VERSION ""

NS_ :

BS_:

BU_: ICC DVR EPC BBCM EAMP CMSM SBOX FLZCU_HCU_IC FLZCU_IC HCU_IC FLZCU_Signal_IC CGW TBOX BNCM CWC FRZCU

BO_ 1265 ICC_ZCU_25: 24 ICC
 SG_ ICC_PwrOff : 18|1@0+ (1,0) [0|1] ""  FLZCU_HCU_IC
 SG_ ICC_EtmEgySave : 20|1@0+ (1,0) [0|1] ""  FLZCU_HCU_IC
 SG_ ICC_HoodSW : 23|2@0+ (1,0) [0|3] ""  FLZCU_HCU_IC
 SG_ ICC_GloveboxSW : 25|2@0+ (1,0) [0|3] ""  FLZCU_HCU_IC
 SG_ ICC_ChrgPortCover_Switch : 27|2@0+ (1,0) [0|3] ""  FLZCU_HCU_IC
 SG_ ICC_ReWinDefrstSwt : 29|2@0+ (1,0) [0|3] ""  FLZCU_HCU_IC,FLZCU_IC
 SG_ ICC_RearMirrorFoldCmd : 31|2@0+ (1,0) [0|3] ""  FLZCU_HCU_IC,FLZCU_IC
 SG_ ICC_CenterLockSwt : 33|2@0+ (1,0) [0|3] ""  FLZCU_HCU_IC,FLZCU_IC
 SG_ ICC_ReverseExtMirrorSts : 36|3@0+ (1,0) [0|7] ""  FLZCU_HCU_IC,FLZCU_IC
 SG_ ICC_LightMainSwitchSts : 39|3@0+ (1,0) [0|7] ""  FLZCU_HCU_IC
 SG_ ICC_AutoFoldSts : 41|2@0+ (1,0) [0|3] ""  FLZCU_HCU_IC,FLZCU_IC
 SG_ ICC_HeadlampHeightSts : 44|3@0+ (1,0) [0|7] ""  FLZCU_HCU_IC,FLZCU_IC
 SG_ ICC_WiprSnvty : 47|3@0+ (1,0) [0|7] ""  FLZCU_HCU_IC,FLZCU_IC
 SG_ ICC_WindowCmd : 52|5@0+ (1,0) [0|31] ""  FLZCU_HCU_IC,FLZCU_IC
 SG_ ICC_LowBeamDelayOff : 55|3@0+ (1,0) [0|7] ""  FLZCU_HCU_IC,FLZCU_IC
 SG_ ICC_FLWinCmd : 62|7@0+ (1,-1) [-1|100] "%"  FLZCU_HCU_IC,FLZCU_IC
 SG_ ICC_FRWinCmd : 86|7@0+ (1,-1) [-1|100] "%"  FLZCU_HCU_IC,FLZCU_IC
 SG_ ICC_RLWinCmd : 94|7@0+ (1,-1) [-1|100] "%"  FLZCU_HCU_IC,FLZCU_IC
 SG_ ICC_RRWinCmd : 102|7@0+ (1,-1) [-1|100] "%"  FLZCU_HCU_IC,FLZCU_IC
 SG_ ICC_FGHeatSts : 105|2@0+ (1,0) [0|3] ""  FLZCU_HCU_IC,FLZCU_IC
 SG_ ICC_AutolockSts : 107|2@0+ (1,0) [0|3] ""  FLZCU_HCU_IC,FLZCU_IC
 SG_ ICC_WiperID : 109|2@0+ (1,0) [0|3] ""  FLZCU_HCU_IC
 SG_ ICC_MaintenanceMode : 111|2@0+ (1,0) [0|3] ""  FLZCU_HCU_IC
 SG_ ICC_lockSetSwitchSts : 113|2@0+ (1,0) [0|3] ""  FLZCU_HCU_IC
 SG_ ICC_ChildLockSW : 115|2@0+ (1,0) [0|3] ""  FLZCU_HCU_IC
 SG_ ICC_ParkUnlockEnable : 117|2@0+ (1,0) [0|3] ""  FLZCU_HCU_IC,FLZCU_IC
 SG_ ICC_BLEOpenDriverDoorEnable : 119|2@0+ (1,0) [0|3] ""  FLZCU_HCU_IC,FLZCU_IC
 SG_ ICC_WinInhbSwt : 121|2@0+ (1,0) [0|3] ""  FLZCU_HCU_IC
 SG_ ICC_SteerWhlHeatgSwt : 124|3@0+ (1,0) [0|7] ""  FLZCU_HCU_IC,FLZCU_IC
 SG_ ICC_AutoHeatingset : 127|2@0+ (1,0) [0|3] ""  FLZCU_HCU_IC
 SG_ ICC_FrontFogSw : 145|2@0+ (1,0) [0|3] ""  FLZCU_HCU_IC
 SG_ ICC_RearFogSw : 147|2@0+ (1,0) [0|3] ""  FLZCU_HCU_IC
 SG_ ICC_DoorControlSW : 149|2@0+ (1,0) [0|3] ""  FLZCU_HCU_IC
 SG_ ICC_LockCarWinCloseSw : 151|2@0+ (1,0) [0|3] ""  FLZCU_HCU_IC,FLZCU_IC
 SG_ ICC_RainCarWinCloseSw : 159|2@0+ (1,0) [0|3] ""  FLZCU_HCU_IC
 SG_ ICC_EasyEntryExitSet : 157|2@0+ (1,0) [0|3] ""  FLZCU_HCU_IC,FLZCU_IC
 SG_ ICC_NapTimeSet : 166|6@0+ (1,-1) [-1|60] "min"  FLZCU_HCU_IC,FLZCU_IC
 SG_ ICC_NapAreaSet : 155|2@0+ (1,0) [0|3] ""  FLZCU_HCU_IC,FLZCU_IC
 SG_ ICC_NapStatusSet : 153|2@0+ (1,0) [0|3] ""  FLZCU_HCU_IC,FLZCU_IC
 SG_ ICC_NapCFSStatusSet : 175|2@0+ (1,0) [0|3] ""  FLZCU_HCU_IC,FRZCU
 SG_ ICC_NapSetTemperature : 173|5@0+ (0.5,15.5) [15.5|30.5] "℃"  FLZCU_HCU_IC,FRZCU
 SG_ ICC_SpoilerWelcomeFunSet : 183|2@0+ (1,0) [0|3] ""  FLZCU_HCU_IC
 SG_ ICC_SpoilerCtrlCmd : 181|3@0+ (1,0) [0|7] ""  FLZCU_HCU_IC
 SG_ ICC_HazardLightReq : 177|2@0+ (1,0) [0|3] ""  FLZCU_HCU_IC
 SG_ ICC_MusicStatus : 187|2@0+ (1,0) [0|3] ""  FLZCU_HCU_IC,FLZCU_IC
 SG_ ICC_CinemaStatus : 185|2@0+ (1,0) [0|3] ""  BBCM,FLZCU_HCU_IC,FLZCU_IC,HCU_IC

BO_ 1137 ICC_TBOX_27: 32 ICC
 SG_ ICC_ElectronicFenceStsFed_471h : 233|2@0+ (1,0) [0|3] ""  FLZCU_HCU_IC,HCU_IC
 SG_ ICC_GPSSailingSpeed_471h : 189|6@0+ (0.1,0) [0|6.3] ""  FLZCU_HCU_IC,HCU_IC
 SG_ ICC_BookChrgSetReq : 23|2@0+ (1,0) [0|3] ""  FLZCU_HCU_IC,HCU_IC,TBOX
 SG_ ICC_BkChrgStartTimeYear : 31|16@0+ (1,1900) [1900|9999] "年"  FLZCU_HCU_IC,HCU_IC,TBOX
 SG_ ICC_BkChrgStartTimeDay : 47|5@0+ (1,0) [1|31] "日"  FLZCU_HCU_IC,HCU_IC,TBOX
 SG_ ICC_BkChrgStartTimeHour : 55|5@0+ (1,0) [0|23] "小时"  FLZCU_HCU_IC,HCU_IC,TBOX
 SG_ ICC_BkChrgStartTimemMin : 63|6@0+ (1,0) [0|59] "分钟"  FLZCU_HCU_IC,HCU_IC,TBOX
 SG_ ICC_BkChrgStartTimeMonth : 87|4@0+ (1,0) [1|12] "月"  FLZCU_HCU_IC,HCU_IC,TBOX
 SG_ ICC_BkChrgDuration : 83|11@0+ (1,0) [0|1440] "min"  FLZCU_HCU_IC,HCU_IC,TBOX
 SG_ ICC_BkChrgCycleType : 103|3@0+ (1,0) [0|7] ""  FLZCU_HCU_IC,HCU_IC,TBOX
 SG_ ICC_StopChrgReq : 100|2@0+ (1,0) [0|3] ""  FLZCU_HCU_IC,HCU_IC,TBOX
 SG_ ICC_BkChrgCycleMon : 98|2@0+ (1,0) [0|3] ""  FLZCU_HCU_IC,HCU_IC,TBOX
 SG_ ICC_BkChrgCycleTues : 111|2@0+ (1,0) [0|3] ""  FLZCU_HCU_IC,HCU_IC,TBOX
 SG_ ICC_BkChrgCycleWen : 109|2@0+ (1,0) [0|3] ""  FLZCU_HCU_IC,HCU_IC,TBOX
 SG_ ICC_BkChrgCycleThur : 107|2@0+ (1,0) [0|3] ""  FLZCU_HCU_IC,HCU_IC,TBOX
 SG_ ICC_BkChrgCycleFri : 105|2@0+ (1,0) [0|3] ""  FLZCU_HCU_IC,HCU_IC,TBOX
 SG_ ICC_BkChrgCycleSat : 119|2@0+ (1,0) [0|3] ""  FLZCU_HCU_IC,HCU_IC,TBOX
 SG_ ICC_BkChrgCycleSun : 117|2@0+ (1,0) [0|3] ""  FLZCU_HCU_IC,HCU_IC,TBOX
 SG_ ICC_KeepWarmStrt : 124|5@0+ (1,0) [1|31] "日"  FLZCU_HCU_IC,HCU_IC,TBOX
 SG_ ICC_KeepWarmStrtHour : 148|5@0+ (1,0) [0|23] "小时"  FLZCU_HCU_IC,HCU_IC,TBOX
 SG_ ICC_KeepWarmStrtMin : 157|6@0+ (1,0) [0|59] "分钟"  FLZCU_HCU_IC,HCU_IC,TBOX
 SG_ ICC_PetmodeFb : 159|2@0+ (1,0) [0|3] ""  FLZCU_HCU_IC,HCU_IC,TBOX
 SG_ ICC_SentinelModeSwitchSts : 167|2@0+ (1,0) [0|3] ""  FLZCU_HCU_IC,HCU_IC,TBOX
 SG_ ICC_SentinelModeWorkingSts : 165|3@0+ (1,0) [0|7] ""  FLZCU_HCU_IC,HCU_IC,TBOX
 SG_ ICC_SentinelModeFaultSts : 161|2@0+ (1,0) [0|3] ""  FLZCU_HCU_IC,HCU_IC,TBOX
 SG_ ICC_SentinelModeAlarmSts : 175|2@0+ (1,0) [0|3] ""  FLZCU_HCU_IC,HCU_IC,TBOX
 SG_ ICC_SentinelModeExitReason : 173|3@0+ (1,0) [0|7] ""  FLZCU_HCU_IC,HCU_IC,TBOX
 SG_ ICC_PetModeWarn : 170|3@0+ (1,0) [0|7] ""  FLZCU_HCU_IC
 SG_ ICC_TBOXPetmodeReq : 178|2@0+ (1,0) [0|3] ""  FLZCU_HCU_IC,TBOX
 SG_ ICC_PetModeWarn_2 : 183|5@0+ (1,0) [0|31] ""  FLZCU_HCU_IC,HCU_IC,TBOX
 SG_ ICM_FuelLevel : 215|8@0+ (1,0) [0|255] "L"  FLZCU_HCU_IC,HCU_IC,TBOX,BNCM
 SG_ ICM_AverageVehicleSpeed : 223|8@0+ (1,0) [0|255] "Km/h"  FLZCU_HCU_IC,HCU_IC,TBOX
 SG_ ICM_DistenceToEmpty_Km : 231|11@0+ (1,0) [0|2047] "km"  FLZCU_HCU_IC,HCU_IC,TBOX
 SG_ ICM_FuelLevelFailSts : 235|1@0+ (1,0) [0|1] ""  FLZCU_HCU_IC,HCU_IC,TBOX
 SG_ ICM_Maintenance_tips : 234|1@0+ (1,0) [0|1] ""  FLZCU_HCU_IC,HCU_IC,TBOX
 SG_ ICM_SumTrip : 247|14@0+ (1,0) [0|16383] "km"  FLZCU_HCU_IC,HCU_IC,TBOX

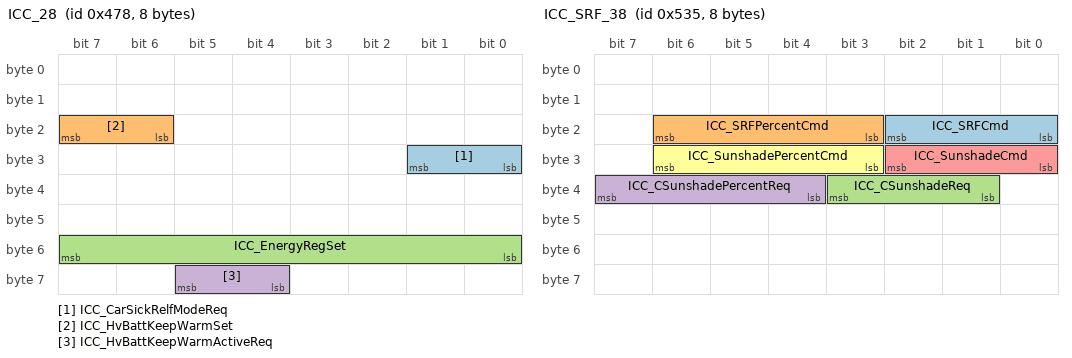
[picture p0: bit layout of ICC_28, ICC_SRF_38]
BO_ 1144 ICC_28: 8 ICC
 SG_ ICC_CarSickRelfModeReq : 25|2@0+ (1,0) [0|3] ""  FLZCU_HCU_IC,HCU_IC
 SG_ ICC_HvBattKeepWarmSet : 23|2@0+ (1,0) [0|3] ""  FLZCU_HCU_IC,HCU_IC,TBOX
 SG_ ICC_EnergyRegSet : 55|8@0+ (1,-1) [-1|100] "%"  FLZCU_HCU_IC
 SG_ ICC_HvBattKeepWarmActiveReq : 61|2@0+ (1,0) [0|3] ""  FLZCU_HCU_IC,HCU_IC,TBOX

BO_ 1210 ICC_ZCU_29: 32 ICC
 SG_ ICC_1_IDverify : 247|2@0+ (1,0) [0|3] ""  FLZCU_HCU_IC
 SG_ ICC_FLSeatHeiCmd : 23|2@0+ (1,0) [0|3] ""  FLZCU_HCU_IC
 SG_ ICC_FLSeatLvlCmd : 21|2@0+ (1,0) [0|3] ""  FLZCU_HCU_IC
 SG_ ICC_FLSeatBackAgCmd : 19|2@0+ (1,0) [0|3] ""  FLZCU_HCU_IC
 SG_ ICC_FLSeatCushCmd : 17|2@0+ (1,0) [0|3] ""  FLZCU_HCU_IC
 SG_ ICC_FLSeatLegSpprtCmd : 31|2@0+ (1,0) [0|3] ""  FLZCU_HCU_IC
 SG_ ICC_FRSeatHeiCmd : 29|2@0+ (1,0) [0|3] ""  FLZCU_HCU_IC
 SG_ ICC_FRSeatLvlCmd : 27|2@0+ (1,0) [0|3] ""  FLZCU_HCU_IC
 SG_ ICC_FRSeatBackAgCmd : 25|2@0+ (1,0) [0|3] ""  FLZCU_HCU_IC
 SG_ ICC_FRSeatLegSpprtCmd : 39|2@0+ (1,0) [0|3] ""  FLZCU_HCU_IC
 SG_ ICC_MemoryRecoveryCmd : 37|2@0+ (1,0) [0|3] ""  FLZCU_HCU_IC,FLZCU_IC
 SG_ ICC_DeleteFaceID : 35|3@0+ (1,0) [0|7] ""  FLZCU_HCU_IC,FLZCU_IC
 SG_ ICC_FLSeatHeitargetCmd : 47|7@0+ (1,-1) [-1|100] "%"  FLZCU_HCU_IC
 SG_ ICC_FLSeatLvltargetCmd : 55|7@0+ (1,-1) [-1|100] "%"  FLZCU_HCU_IC
 SG_ ICC_FLSeatBackAgtargetCmd : 63|7@0+ (1,-1) [-1|100] "%"  FLZCU_HCU_IC
 SG_ ICC_FLSeatCushtargetCmd : 87|7@0+ (1,-1) [-1|100] "%"  FLZCU_HCU_IC
 SG_ ICC_FLSeatLegSpprttargetCmd : 95|7@0+ (1,-1) [-1|100] "%"  FLZCU_HCU_IC
 SG_ ICC_FRSeatHeitargetCmd : 103|7@0+ (1,-1) [-1|100] "%"  FLZCU_HCU_IC
 SG_ ICC_FRSeatLvltargetCmd : 111|7@0+ (1,-1) [-1|100] "%"  FLZCU_HCU_IC
 SG_ ICC_FRSeatBackAgtargetCmd : 119|7@0+ (1,-1) [-1|100] "%"  FLZCU_HCU_IC
 SG_ ICC_FRSeatLegSpprttargetCmd : 127|7@0+ (1,-1) [-1|100] "%"  FLZCU_HCU_IC
 SG_ ICC_NapFLSeatBackAgtargetSet : 151|7@0+ (1,-1) [-1|100] "%"  FLZCU_HCU_IC,FLZCU_IC
 SG_ ICC_NapFRSeatBackAgtargetSet : 159|7@0+ (1,-1) [-1|100] "%"  FLZCU_HCU_IC,FLZCU_IC
 SG_ ICC_NapFLSeatLvltargetSet : 167|7@0+ (1,-1) [-1|100] "%"  FLZCU_HCU_IC,FLZCU_IC
 SG_ ICC_NapFRSeatLvltargetSet : 175|7@0+ (1,-1) [-1|100] "%"  FLZCU_HCU_IC,FLZCU_IC
 SG_ ICC_FRSeatLegRestAngleCmd : 183|2@0+ (1,0) [0|3] ""  FLZCU_HCU_IC
 SG_ ICC_FRSeatLegRestAngletargetCmd : 190|7@0+ (1,-1) [-1|100] "%"  FLZCU_HCU_IC
 SG_ ICC_FRSeatCushCmd : 181|2@0+ (1,0) [0|3] ""  FLZCU_HCU_IC
 SG_ ICC_FRSeatCushtargetCmd : 214|7@0+ (1,-1) [-1|100] "%"  FLZCU_HCU_IC
 SG_ ICC_FRZeroGravitySeatSw : 179|2@0+ (1,0) [0|3] ""  FLZCU_HCU_IC
 SG_ ICC_HomeLinkArmHornSet : 223|2@0+ (1,0) [0|3] ""  FLZCU_HCU_IC
 SG_ ICC_HomeLinkWelLightSet : 221|2@0+ (1,0) [0|3] ""  FLZCU_HCU_IC
 SG_ ICC_HomeLinkPositionSts : 219|2@0+ (1,0) [0|3] ""  FLZCU_HCU_IC
 SG_ ICC_WelcomeOpenSetCmd : 217|2@0+ (1,0) [0|3] ""  FLZCU_HCU_IC,FLZCU_IC
 SG_ ICC_WALOpenSetCmd : 231|2@0+ (1,0) [0|3] ""  FLZCU_HCU_IC,FLZCU_IC
 SG_ ICC_UIROpenSetCmd : 229|2@0+ (1,0) [0|3] ""  FLZCU_HCU_IC,FLZCU_IC
 SG_ ICC_EnjoyableSeatSwitch : 227|2@0+ (1,0) [0|3] ""  FLZCU_HCU_IC,FLZCU_IC
 SG_ ICC_BLTKeyPESet : 225|2@0+ (1,0) [0|3] ""  FLZCU_HCU_IC,FLZCU_IC
 SG_ ICC_FRMemoryDeleteCmd : 241|2@0+ (1,0) [0|3] ""  FLZCU_HCU_IC
 SG_ ICC_FLSitPosnlocation : 233|2@0+ (1,0) [0|3] ""  FLZCU_HCU_IC,FLZCU_IC
 SG_ ICC_FRSitPosnlocation : 235|2@0+ (1,0) [0|3] ""  FLZCU_HCU_IC
 SG_ ICC_FREasyEntryExitSet : 237|2@0+ (1,0) [0|3] ""  FLZCU_HCU_IC
 SG_ ICC_FRMemoryRecoveryCmd : 239|2@0+ (1,0) [0|3] ""  FLZCU_HCU_IC
 SG_ ICC_ConsoleAdjustSwitch : 245|4@0+ (1,0) [0|15] ""  FLZCU_HCU_IC

BO_ 1399 ICC_TBOX_31: 32 ICC
 SG_ ICC_SailremainingTime_577h : 223|8@0+ (1,0) [0|255] ""  FLZCU_HCU_IC,FLZCU_IC
 SG_ TotalSailOdoMeterBackUp_577h : 183|16@0+ (0.1,0) [0|6553.5] ""  FLZCU_HCU_IC,FLZCU_IC,HCU_IC
 SG_ SailOdoMeter_577h : 167|8@0+ (0.1,0) [0|25.5] ""  FLZCU_HCU_IC,FLZCU_IC
 SG_ MaintenanceOdometer_577h : 239|24@0+ (0.1,0) [0|999999.9] ""  FLZCU_HCU_IC,FLZCU_IC
 SG_ MaintenanceOdometer_BkpEn_577h : 226|2@0+ (1,0) [0|3] ""  FLZCU_HCU_IC,FLZCU_IC
 SG_ MaintenanceOdometer_Valid_577h : 224|1@0+ (1,0) [0|1] ""  FLZCU_HCU_IC,FLZCU_IC
 SG_ ICC_CLTC_RangeAval : 1|10@0+ (1,0) [0|1022] "KM"  TBOX
 SG_ ICC_DynamicRangeAval : 17|10@0+ (1,0) [0|1022] "KM"  TBOX
 SG_ ICC_WLTC_RangeAval : 33|10@0+ (1,0) [0|1022] "KM"  TBOX
 SG_ ICC_CLTC_RangeAvalFuel : 51|12@0+ (1,0) [0|2000] "KM"  TBOX
 SG_ ICC_WLTC_RangeAvalFuel : 67|12@0+ (1,0) [0|2000] "KM"  TBOX
 SG_ ICC_DynamicRangeAvalFuel : 83|12@0+ (1,0) [0|2000] "KM"  TBOX
 SG_ ICC_CLTC_RangeAvalComp : 99|12@0+ (1,0) [0|2000] "KM"  TBOX
 SG_ ICC_WLTC_RangeAvalComp : 115|12@0+ (1,0) [0|2000] "KM"  TBOX
 SG_ ICC_DynamicRangeAvalComp : 131|12@0+ (1,0) [0|2000] "KM"  TBOX
 SG_ ICC_Conditiontype : 151|2@0+ (1,0) [0|3] ""  TBOX

BO_ 1238 ICC_TMS_32: 32 ICC
 SG_ ICC_CFSSwitch : 17|2@0+ (1,0) [0|3] "" Vector__XXX
 SG_ ICC_CFSLevelSet : 20|3@0+ (1,0) [0|7] "" Vector__XXX
 SG_ ICC_CFSPosSet : 23|2@0+ (1,0) [0|3] "" Vector__XXX
 SG_ ICC_PM25Switch : 25|2@0+ (1,0) [0|3] "" Vector__XXX
 SG_ ICC_AQSSwitch : 27|2@0+ (1,0) [0|3] "" Vector__XXX
 SG_ ICC_SecSetTemp_C : 36|5@0+ (0.5,15.5) [15.5|30.5] "℃" Vector__XXX
 SG_ ICC_SecFaceKeySts : 39|2@0+ (1,0) [0|3] "" Vector__XXX
 SG_ ICC_SecFootKeySts : 41|2@0+ (1,0) [0|3] "" Vector__XXX
 SG_ ICC_SecBlowSpeedLevelKeySts : 45|4@0+ (1,0) [0|15] "" Vector__XXX
 SG_ ICC_SecAutoSwitch : 47|2@0+ (1,0) [0|3] "" Vector__XXX
 SG_ ICC_SecCLMSwitch : 49|2@0+ (1,0) [0|3] "" Vector__XXX
 SG_ ICC_ThrSetTemp_C : 54|5@0+ (0.5,15.5) [15.5|30.5] "℃" Vector__XXX
 SG_ ICC_ThrFaceKeySts : 57|2@0+ (1,0) [0|3] "" Vector__XXX
 SG_ ICC_ThrFootKeySts : 59|2@0+ (1,0) [0|3] "" Vector__XXX
 SG_ ICC_ThrBlowSpeedLevelKeySts : 63|4@0+ (1,0) [0|15] "" Vector__XXX
 SG_ ICC_ThrAutoSwitch : 81|2@0+ (1,0) [0|3] "" Vector__XXX
 SG_ ICC_ThrCLMSwitch : 83|2@0+ (1,0) [0|3] "" Vector__XXX
 SG_ ICC_ThrACRequestKeySts : 85|2@0+ (1,0) [0|3] "" Vector__XXX
 SG_ ICC_DFMSwitch : 87|2@0+ (1,0) [0|3] "" Vector__XXX

BO_ 1289 ICC_34: 32 ICC
 SG_ ICC_TirePressureDisplayUnit : 23|2@0+ (1,0) [0|3] ""  TBOX
 SG_ ICC_TireTemperatureDisplayUnit : 21|2@0+ (1,0) [0|3] ""  TBOX
 SG_ ICC_ToggleUnits : 19|2@0+ (1,0) [0|3] ""  TBOX
 SG_ ICC_BtConFlag : 28|3@0+ (1,0) [0|7] ""  SBOX,TBOX
 SG_ ICC_GPSSwitchSet : 25|2@0+ (1,0) [0|3] ""  TBOX

BO_ 1167 ICC_35: 32 ICC
 SG_ ICC_WadeModeSet_48Fh : 146|3@0+ (1,0) [0|7] "" Vector__XXX
 SG_ ICC_DeepSnowSet_48Fh : 121|2@0+ (1,0) [0|3] ""  FLZCU_HCU_IC,HCU_IC
 SG_ ICC_KeyDriveModememory : 17|2@0+ (1,0) [0|3] ""  FLZCU_HCU_IC,HCU_IC
 SG_ ICC_DriveModeSet : 22|5@0+ (1,0) [0|31] ""  FLZCU_HCU_IC,HCU_IC
 SG_ ICC_DRIFTModeSetReq : 25|2@0+ (1,0) [0|3] ""  FLZCU_HCU_IC,HCU_IC
 SG_ ICC_EXPERTEIPBESPSet : 27|2@0+ (1,0) [0|3] ""  FLZCU_HCU_IC,HCU_IC
 SG_ ICC_EXPERTEcoSet : 29|2@0+ (1,0) [0|3] ""  FLZCU_HCU_IC,HCU_IC
 SG_ ICC_EXPERTNormSet : 31|2@0+ (1,0) [0|3] ""  FLZCU_HCU_IC,HCU_IC
 SG_ ICC_EXPERTSportSet : 33|2@0+ (1,0) [0|3] ""  FLZCU_HCU_IC,HCU_IC
 SG_ ICC_CrossaxisSet : 35|2@0+ (1,0) [0|3] ""  FLZCU_HCU_IC,HCU_IC
 SG_ ICC_EXPERTRWDSet : 37|2@0+ (1,0) [0|3] ""  FLZCU_HCU_IC,HCU_IC
 SG_ ICC_EXPERTAWDSet : 39|2@0+ (1,0) [0|3] ""  FLZCU_HCU_IC,HCU_IC
 SG_ ICC_EXPERTAutoSet : 41|2@0+ (1,0) [0|3] ""  FLZCU_HCU_IC,HCU_IC
 SG_ ICC_CLIMBSet : 43|2@0+ (1,0) [0|3] ""  FLZCU_HCU_IC,HCU_IC
 SG_ ICC_DriveModeExitSet : 45|2@0+ (1,0) [0|3] ""  FLZCU_HCU_IC,HCU_IC
 SG_ ICC_Confidencelevel : 62|7@0+ (1,-1) [0|100] "%"  FLZCU_HCU_IC,HCU_IC
 SG_ ICC_V2L_IntlDisChg : 81|2@0+ (1,0) [0|3] ""  FLZCU_HCU_IC,HCU_IC
 SG_ ICC_ExhibitionModeSwitch : 83|2@0+ (1,0) [0|3] ""  FLZCU_HCU_IC,FLZCU_IC,HCU_IC
 SG_ ICC_TrailerMode : 85|2@0+ (1,0) [0|3] ""  FLZCU_HCU_IC,HCU_IC
 SG_ ICC_V2L_DisChgMem : 87|2@0+ (1,0) [0|3] ""  FLZCU_HCU_IC,HCU_IC
 SG_ ICC_DrivePowerDispSet : 89|2@0+ (1,0) [0|3] ""  FLZCU_HCU_IC,HCU_IC
 SG_ ICC_WLTC_to_CLTC_Mode : 91|2@0+ (1,0) [0|3] ""  FLZCU_HCU_IC,HCU_IC
 SG_ ICC_StopChrgnSwitch : 93|2@0+ (1,0) [0|3] ""  FLZCU_HCU_IC,HCU_IC
 SG_ ICC_StopChrgnMode : 95|2@0+ (1,0) [0|3] ""  FLZCU_HCU_IC,HCU_IC
 SG_ ICC_RegenerateLevelCtrl : 98|3@0+ (1,0) [0|7] ""  FLZCU_HCU_IC,HCU_IC
 SG_ ICC_SinglePedalMem : 100|2@0+ (1,0) [0|3] ""  FLZCU_HCU_IC,HCU_IC
 SG_ ICC_FuelDetnSwt : 102|2@0+ (1,0) [0|3] ""  FLZCU_HCU_IC,HCU_IC
 SG_ ICC_FuelDetnState : 105|2@0+ (1,0) [0|3] ""  FLZCU_HCU_IC,HCU_IC
 SG_ ICC_FuelDetnOpDefeated : 107|2@0+ (1,0) [0|3] ""  FLZCU_HCU_IC,HCU_IC
 SG_ ICC_HVDownRepairMode : 109|2@0+ (1,0) [0|3] ""  FLZCU_HCU_IC,HCU_IC
 SG_ ICC_UTURNSnowSet : 111|2@0+ (1,0) [0|3] ""  FLZCU_HCU_IC,HCU_IC
 SG_ ICC_UTURNSandSet : 113|2@0+ (1,0) [0|3] ""  FLZCU_HCU_IC,HCU_IC
 SG_ ICC_UTURNMudSet : 115|2@0+ (1,0) [0|3] ""  FLZCU_HCU_IC,HCU_IC
 SG_ ICC_UTURNGrassSet : 117|2@0+ (1,0) [0|3] ""  FLZCU_HCU_IC,HCU_IC
 SG_ ICC_LTCDispSet2 : 124|2@0+ (1,0) [0|3] ""  FLZCU_HCU_IC,HCU_IC
 SG_ ICC_SetSocManage : 127|3@0+ (1,0) [0|7] ""  FLZCU_HCU_IC,HCU_IC

BO_ 1326 ICC_BD_36: 8 ICC
 SG_ ICC_DWDOnOff_Req : 17|2@0+ (1,0) [0|3] "" Vector__XXX
 SG_ ICC_ContainerLightSet : 19|2@0+ (1,0) [0|3] ""  FLZCU_HCU_IC,FLZCU_IC

BO_ 1331 ICC_IC_37: 32 ICC
 SG_ Set_AMPKeyVolume : 119|6@0+ (1,0) [0|63] ""  EAMP
 SG_ ICC_RLSeatEasyEntryExitSet : 17|2@0+ (1,0) [0|3] ""  BBCM
 SG_ ICC_RRSeatEasyEntryExitSet : 19|2@0+ (1,0) [0|3] ""  BBCM
 SG_ ICC_RLMemoryRecoveryCmd : 21|2@0+ (1,0) [0|3] ""  BBCM
 SG_ ICC_RRMemoryRecoveryCmd : 23|2@0+ (1,0) [0|3] ""  BBCM
 SG_ ICC_RLSitPosnlocation : 25|2@0+ (1,0) [0|3] ""  BBCM
 SG_ ICC_RRSitPosnlocation : 27|2@0+ (1,0) [0|3] ""  BBCM
 SG_ ICC_CMSMDisplaySwitch : 29|2@0+ (1,0) [0|3] ""  CMSM
 SG_ ICC_CMSMDisplayAdjustmode : 31|2@0+ (1,0) [0|3] ""  CMSM
 SG_ ICC_CMSMSetstandardSwitch : 33|2@0+ (1,0) [0|3] ""  CMSM
 SG_ ICC_LeftPedalControl : 35|2@0+ (1,0) [0|3] ""  EPC
 SG_ ICC_RightPedalControl : 37|2@0+ (1,0) [0|3] ""  EPC
 SG_ ICC_EPCEnable : 39|2@0+ (1,0) [0|3] ""  EPC
 SG_ ICC_AMPKTVvoiceVolumeSet : 45|6@0+ (1,0) [0|63] ""  EAMP
 SG_ ICC_AMPA2BENCSoundReq : 47|2@0+ (1,0) [0|3] ""  EAMP
 SG_ ICC_AMPENCVolumeSet : 53|6@0+ (1,0) [0|63] ""  EAMP
 SG_ ICC_AMPA2BChimeSoundReq : 55|2@0+ (1,0) [0|3] ""  EAMP
 SG_ Set_AMPSoundFocus_2 : 63|4@0+ (1,0) [0|15] ""  EAMP
 SG_ ICC_AMPA2BKTVvoiceSoundReq : 58|3@0+ (1,0) [0|7] ""  EAMP
 SG_ ICC_MedStatusSet : 81|2@0+ (1,0) [0|3] ""  FLZCU_HCU_IC,FLZCU_IC
 SG_ ICC_MedAreaSet : 87|4@0+ (1,0) [0|15] ""  BBCM,FLZCU_HCU_IC,FLZCU_IC
 SG_ ICC_LeftElectricPedalsSet : 89|2@0+ (1,0) [0|3] ""  EPC
 SG_ ICC_RightElectricPedalsSet : 91|2@0+ (1,0) [0|3] ""  EPC
 SG_ ICC_NapAreaSet2 : 95|3@0+ (1,0) [0|7] ""  BBCM,FLZCU_HCU_IC,FLZCU_IC
 SG_ ICC_DisplayAdjustrAngReq : 103|8@0+ (1,0) [0|255] "°"  CMSM
 SG_ ICC_CMSMTouchSts : 123|2@0+ (1,0) [0|3] ""  CMSM

BO_ 1333 ICC_SRF_38: 8 ICC
 SG_ ICC_SRFCmd : 18|3@0+ (1,0) [0|7] ""  FLZCU_HCU_IC
 SG_ ICC_SRFPercentCmd : 22|4@0+ (1,0) [0|15] ""  FLZCU_HCU_IC
 SG_ ICC_CSunshadeReq : 35|3@0+ (1,0) [0|7] ""  FLZCU_HCU_IC
 SG_ ICC_CSunshadePercentReq : 39|4@0+ (1,0) [0|15] ""  FLZCU_HCU_IC
 SG_ ICC_SunshadeCmd : 26|3@0+ (1,0) [0|7] ""  FLZCU_HCU_IC
 SG_ ICC_SunshadePercentCmd : 30|4@0+ (1,0) [0|15] ""  FLZCU_HCU_IC

BO_ 1335 ICC_CH_39: 32 ICC
 SG_ ICC_SandABSCmd_537h : 43|2@0+ (1,0) [0|3] ""  CGW
 SG_ ICC_SandABSSw_537h : 41|2@0+ (1,0) [0|3] ""  CGW
 SG_ ICC_UndergroundModeReq_537h : 39|2@0+ (1,0) [0|3] ""  CGW
 SG_ ICC_InflateReq_537h : 37|2@0+ (1,0) [0|3] ""  CGW
 SG_ ICC_TrekThroughReq_537h : 35|2@0+ (1,0) [0|3] ""  CGW
 SG_ New_Signal_537_3 : 55|16@0+ (1,0) [0|65535] ""  CGW
 SG_ New_Signal_537_1 : 23|1@0+ (1,0) [0|1] ""  CGW
 SG_ ICC_RolloverSetCmd : 33|2@0+ (1,0) [0|3] ""  CGW
 SG_ ICC_SET_EPS_SteerReturnRmdSts : 17|2@0+ (1,0) [0|3] ""  CGW
 SG_ ICC_SET_MFSShake : 19|2@0+ (1,0) [0|3] ""  CGW
 SG_ ICC_DMS_1_DistractionLevel : 22|3@0+ (1,0) [0|7] ""  CGW
 SG_ ICC_OverLoadWarnShieldSet : 27|2@0+ (1,0) [0|3] ""  CGW
 SG_ ICC_BSWReq : 29|2@0+ (1,0) [0|3] ""  CGW
 SG_ ICC_horizontalReq : 31|2@0+ (1,0) [0|3] ""  CGW

BO_ 1337 ICC_TMS_40: 16 ICC
 SG_ ICC_SET_BT_ReduceWindSpeed : 17|2@0+ (1,0) [0|3] ""  CGW
 SG_ ICC_SET_IPM_FirstBlowing : 19|2@0+ (1,0) [0|3] ""  CGW
 SG_ ICC_SET_IPM_BlowerDelay : 21|2@0+ (1,0) [0|3] ""  CGW
 SG_ ICC_SET_CirculationInTunnels : 23|2@0+ (1,0) [0|3] ""  CGW
 SG_ ICC_UVCLuminanceReq : 25|2@0+ (1,0) [0|3] ""  CGW
 SG_ ICC_UVCControlReq : 27|2@0+ (1,0) [0|3] ""  CGW
 SG_ ICC_CrossCountryCoolingReq : 29|2@0+ (1,0) [0|3] ""  CGW
 SG_ ICC_KeepWarmReq : 31|2@0+ (1,0) [0|3] ""  CGW
 SG_ ICC_keepwarmSetTemperatureReq : 39|8@0+ (1,0) [0|255] ""  CGW
 SG_ ICC_ParkingAirConditioning : 41|2@0+ (1,0) [0|3] ""  CGW
 SG_ ICC_CoolantFill_Req : 43|2@0+ (1,0) [0|3] ""  CGW
 SG_ ICC_FraganceLightoffReq : 45|2@0+ (1,0) [0|3] ""  CGW
 SG_ ICC_FraganceMemoffReq : 47|2@0+ (1,0) [0|3] ""  CGW
 SG_ ICC_AirPurgeReminderReq : 55|2@0+ (1,0) [0|3] ""  CGW
 SG_ ICC_BiochemicalFuncReq : 59|2@0+ (1,0) [0|3] ""  CGW
 SG_ ICC_TimedVentilationReq : 57|2@0+ (1,0) [0|3] ""  CGW
 SG_ ICC_PetmodeSetTemperature_L_C : 87|5@0+ (0.5,15.5) [15.5|30.5] "℃"  CGW
 SG_ ICC_PetModeSetTemperature_R_C : 82|5@0+ (0.5,15.5) [15.5|30.5] "℃"  CGW
 SG_ ICC_PetModeSetCLMOn : 93|2@0+ (1,0) [0|3] ""  CGW
 SG_ ICC_PetModeSetAutoKeySts : 91|2@0+ (1,0) [0|3] ""  CGW
 SG_ ICC_PetModeSetCirculationSts : 89|2@0+ (1,0) [0|3] ""  CGW

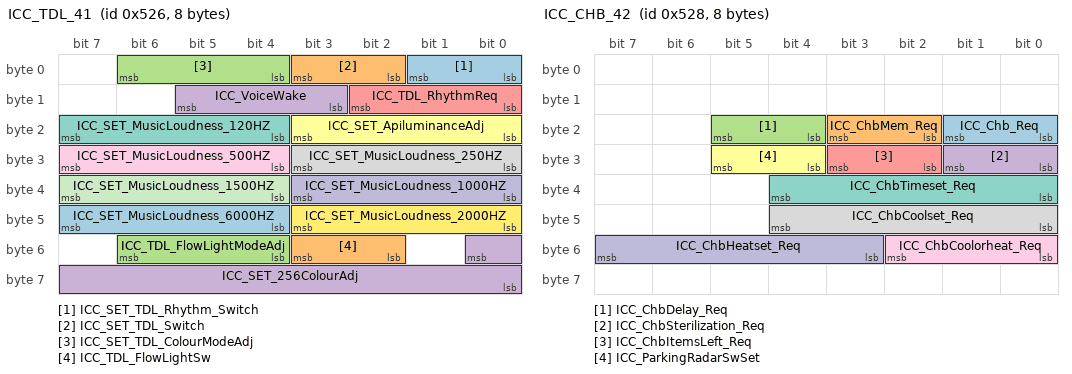
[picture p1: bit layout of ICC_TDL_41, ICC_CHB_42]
BO_ 1318 ICC_TDL_41: 8 ICC
 SG_ ICC_SET_TDL_Rhythm_Switch : 1|2@0+ (1,0) [0|3] ""  FLZCU_HCU_IC
 SG_ ICC_SET_TDL_Switch : 3|2@0+ (1,0) [0|3] ""  FLZCU_HCU_IC
 SG_ ICC_SET_TDL_ColourModeAdj : 6|3@0+ (1,0) [0|7] ""  FLZCU_HCU_IC
 SG_ ICC_VoiceWake : 13|3@0+ (1,0) [0|7] ""  FLZCU_HCU_IC
 SG_ ICC_TDL_RhythmReq : 10|3@0+ (1,0) [0|7] ""  FLZCU_HCU_IC
 SG_ ICC_SET_ApiluminanceAdj : 19|4@0+ (1,0) [0|15] ""  FLZCU_HCU_IC
 SG_ ICC_SET_MusicLoudness_120HZ : 23|4@0+ (1,0) [0|15] ""  FLZCU_HCU_IC
 SG_ ICC_SET_MusicLoudness_250HZ : 27|4@0+ (1,0) [0|15] ""  FLZCU_HCU_IC
 SG_ ICC_SET_MusicLoudness_500HZ : 31|4@0+ (1,0) [0|15] ""  FLZCU_HCU_IC
 SG_ ICC_SET_MusicLoudness_1000HZ : 35|4@0+ (1,0) [0|15] ""  FLZCU_HCU_IC
 SG_ ICC_SET_MusicLoudness_1500HZ : 39|4@0+ (1,0) [0|15] ""  FLZCU_HCU_IC
 SG_ ICC_SET_MusicLoudness_2000HZ : 43|4@0+ (1,0) [0|15] ""  FLZCU_HCU_IC
 SG_ ICC_SET_MusicLoudness_6000HZ : 47|4@0+ (1,0) [0|15] ""  FLZCU_HCU_IC
 SG_ ICC_TDL_FlowLightSw : 51|2@0+ (1,0) [0|3] ""  FLZCU_HCU_IC
 SG_ ICC_TDL_FlowLightModeAdj : 54|3@0+ (1,0) [0|7] ""  FLZCU_HCU_IC
 SG_ ICC_SET_256ColourAdj : 48|9@0+ (1,0) [0|256] ""  FLZCU_HCU_IC

BO_ 1320 ICC_CHB_42: 8 ICC
 SG_ ICC_Chb_Req : 17|2@0+ (1,0) [0|3] "" Vector__XXX
 SG_ ICC_ChbMem_Req : 19|2@0+ (1,0) [0|3] "" Vector__XXX
 SG_ ICC_ChbDelay_Req : 21|2@0+ (1,0) [0|3] "" Vector__XXX
 SG_ ICC_ChbSterilization_Req : 25|2@0+ (1,0) [0|3] "" Vector__XXX
 SG_ ICC_ChbItemsLeft_Req : 27|2@0+ (1,0) [0|3] "" Vector__XXX
 SG_ ICC_ParkingRadarSwSet : 29|2@0+ (1,0) [0|3] "" Vector__XXX
 SG_ ICC_ChbTimeset_Req : 36|5@0+ (1,0) [0|31] "h" Vector__XXX
 SG_ ICC_ChbCoolset_Req : 44|5@0+ (1,0) [0|31] "" Vector__XXX
 SG_ ICC_ChbCoolorheat_Req : 50|3@0+ (1,0) [0|7] "" Vector__XXX
 SG_ ICC_ChbHeatset_Req : 55|5@0+ (1,0) [0|31] "" Vector__XXX

BO_ 1360 ICC_LC_42: 64 ICC
 SG_ ICC_LISD_DisplaySwitch : 1|2@0+ (1,0) [0|3] "" Vector__XXX
 SG_ ICC_LISD_ParkingShowCMD : 3|2@0+ (1,0) [0|3] "" Vector__XXX
 SG_ ICC_RoofCampLampSetL : 5|2@0+ (1,0) [0|3] ""  FLZCU_HCU_IC,FLZCU_Signal_IC
 SG_ ICC_RISD_DisplaySwitch : 7|2@0+ (1,0) [0|3] "" Vector__XXX
 SG_ ICC_RISD_ParkingShowCMD : 9|2@0+ (1,0) [0|3] "" Vector__XXX
 SG_ ICC_RoofCampLampSetR : 11|2@0+ (1,0) [0|3] ""  FLZCU_HCU_IC,FLZCU_Signal_IC
 SG_ ICC_LogoParkingReq : 13|2@0+ (1,0) [0|3] "" Vector__XXX
 SG_ ICC_LogoChargingReq : 15|2@0+ (1,0) [0|3] ""  FLZCU_HCU_IC,FLZCU_IC
 SG_ ICC_DRLSw : 17|2@0+ (1,0) [0|3] ""  FLZCU_HCU_IC,FLZCU_IC
 SG_ ICC_TopLightSet : 19|2@0+ (1,0) [0|3] ""  FLZCU_HCU_IC,FLZCU_Signal_IC
 SG_ ICC_APillarYellowAmbientSet : 21|2@0+ (1,0) [0|3] ""  FLZCU_HCU_IC,FLZCU_Signal_IC
 SG_ ICC_APillarWhiteAmbientSet : 23|2@0+ (1,0) [0|3] ""  FLZCU_HCU_IC,FLZCU_Signal_IC
 SG_ ICC_LISD_ParkingShowMod : 27|4@0+ (1,0) [0|15] "" Vector__XXX
 SG_ ICC_RISD_ParkingShowMod : 31|4@0+ (1,0) [0|15] "" Vector__XXX
 SG_ ICC_APillarSpotLampSet : 39|2@0+ (1,0) [0|3] ""  FLZCU_HCU_IC,FLZCU_Signal_IC
 SG_ ICC_PenetrationLampSetF : 37|2@0+ (1,0) [0|3] ""  FLZCU_HCU_IC,FLZCU_IC
 SG_ ICC_MusicLampShowSW : 35|2@0+ (1,0) [0|3] ""  FLZCU_HCU_IC,FLZCU_IC
 SG_ ICC_LogoColorReq : 33|9@0+ (1,0) [0|511] "" Vector__XXX
 SG_ ICC_XDriveMode : 40|5@0+ (1,0) [0|31] ""  FLZCU_HCU_IC,HCU_IC

CM_ SG_ 1265 ICC_PwrOff "车辆下电";
CM_ SG_ 1265 ICC_EtmEgySave "极致节能模式";
CM_ SG_ 1265 ICC_HoodSW "前舱盖开关";
CM_ SG_ 1265 ICC_GloveboxSW "手套箱开关";
CM_ SG_ 1265 ICC_ChrgPortCover_Switch "充电口盖开关";
CM_ SG_ 1265 ICC_ReWinDefrstSwt "Rear window defrost后风窗加热";
CM_ SG_ 1265 ICC_RearMirrorFoldCmd "后视镜手动折叠开关";
CM_ SG_ 1265 ICC_CenterLockSwt "CenterLock中控锁开关";
CM_ SG_ 1265 ICC_ReverseExtMirrorSts "DVD设置倒车外后视镜下翻功能开启";
CM_ SG_ 1265 ICC_LightMainSwitchSts "小灯、近光、Auto开关";
CM_ SG_ 1265 ICC_AutoFoldSts "后视镜自动折叠";
CM_ SG_ 1265 ICC_HeadlampHeightSts "大灯高度调节设置信号";
CM_ SG_ 1265 ICC_WiprSnvty "WiperSensitivity雨刮灵敏度";
CM_ SG_ 1265 ICC_WindowCmd "语音控制车窗指令：
1、包含对左前车窗、右前车窗、左后车窗、右后车窗、前排车窗、后排车窗、全部车窗的指令控制；
2、具备open（打开）、close（关闭）、comfort（通风）三种动作指令，目前只有同时控制四个车窗时有comfort指令。
3、没有此功能，其他信号触发此帧报文发送时，此信号发“Not active”；";
CM_ SG_ 1265 ICC_LowBeamDelayOff "大灯延迟关闭开关";
CM_ SG_ 1265 ICC_FLWinCmd "玻璃升降防夹（霍尔、纹波）左前窗";
CM_ SG_ 1265 ICC_FRWinCmd "玻璃升降防夹（霍尔、纹波）右前窗";
CM_ SG_ 1265 ICC_RLWinCmd "玻璃升降防夹（霍尔、纹波）左后窗";
CM_ SG_ 1265 ICC_RRWinCmd "玻璃升降防夹（霍尔、纹波）左后窗";
CM_ SG_ 1265 ICC_FGHeatSts "设置前挡风加热";
CM_ SG_ 1265 ICC_AutolockSts "设置自动落锁模式";
CM_ SG_ 1265 ICC_WiperID "雨刮ID";
CM_ SG_ 1265 ICC_MaintenanceMode "雨刮维修模式开关";
CM_ SG_ 1265 ICC_lockSetSwitchSts "解闭锁设置";
CM_ SG_ 1265 ICC_ChildLockSW "儿童锁开关";
CM_ SG_ 1265 ICC_ParkUnlockEnable "驻车解锁设置";
CM_ SG_ 1265 ICC_BLEOpenDriverDoorEnable "蓝牙靠近开门设置";
CM_ SG_ 1265 ICC_WinInhbSwt "Window Inhibit 玻璃禁止开关";
CM_ SG_ 1265 ICC_SteerWhlHeatgSwt "Steering Wheel heating方向盘加热";
CM_ SG_ 1265 ICC_AutoHeatingset "后视镜自动加热设置";
CM_ SG_ 1265 ICC_FrontFogSw "屏内前雾灯开关";
CM_ SG_ 1265 ICC_RearFogSw "屏内后雾灯开关";
CM_ SG_ 1265 ICC_DoorControlSW "顶灯门控开关";
CM_ SG_ 1265 ICC_LockCarWinCloseSw "锁车自动升窗开关";
CM_ SG_ 1265 ICC_RainCarWinCloseSw "雨天自动升窗开关";
CM_ SG_ 1265 ICC_EasyEntryExitSet "便捷进入\离车";
CM_ SG_ 1265 ICC_NapTimeSet "小憩模式时长设置";
CM_ SG_ 1265 ICC_NapAreaSet "小憩模式开启区域设置";
CM_ SG_ 1265 ICC_NapStatusSet "小憩模式开关设置";
CM_ SG_ 1265 ICC_NapCFSStatusSet "小憩模式香氛系统开关设置";
CM_ SG_ 1265 ICC_NapSetTemperature "小憩模式设置空调温度";
CM_ SG_ 1265 ICC_SpoilerWelcomeFunSet "电动尾翼迎宾功能设置";
CM_ SG_ 1265 ICC_SpoilerCtrlCmd "电动尾翼控制设置";
CM_ SG_ 1265 ICC_HazardLightReq "双闪灯请求";
CM_ SG_ 1265 ICC_MusicStatus "K歌模式状态";
CM_ SG_ 1265 ICC_CinemaStatus "影院模式状态";
CM_ SG_ 1137 ICC_BookChrgSetReq "预约充电开启/取消设置请求";
CM_ SG_ 1137 ICC_BkChrgStartTimeYear "预约充电开始时间设置-年";
CM_ SG_ 1137 ICC_BkChrgStartTimeDay "预约充电开始时间设置-日";
CM_ SG_ 1137 ICC_BkChrgStartTimeHour "预约充电开始时间设置-时";
CM_ SG_ 1137 ICC_BkChrgStartTimemMin "预约充电开始时间设置-分";
CM_ SG_ 1137 ICC_BkChrgStartTimeMonth "预约充电开始时间设置-月";
CM_ SG_ 1137 ICC_BkChrgDuration "本地预约充电时长设置";
CM_ SG_ 1137 ICC_BkChrgCycleType "本地预约充电周期循环方式";
CM_ SG_ 1137 ICC_StopChrgReq "结束充电请求";
CM_ SG_ 1137 ICC_BkChrgCycleMon "预约充电周期循环_每周一循环";
CM_ SG_ 1137 ICC_BkChrgCycleTues "预约充电周期循环_每周二循环";
CM_ SG_ 1137 ICC_BkChrgCycleWen "预约充电周期循环_每周三循环";
CM_ SG_ 1137 ICC_BkChrgCycleThur "预约充电周期循环_每周四循环";
CM_ SG_ 1137 ICC_BkChrgCycleFri "预约充电周期循环_每周五循环";
CM_ SG_ 1137 ICC_BkChrgCycleSat "预约充电周期循环_每周六循环";
CM_ SG_ 1137 ICC_BkChrgCycleSun "预约充电周期循环_每周日循环";
CM_ SG_ 1137 ICC_KeepWarmStrt "插枪保温开始时间设置-日";
CM_ SG_ 1137 ICC_KeepWarmStrtHour "插枪保温开始时间设置-时";
CM_ SG_ 1137 ICC_KeepWarmStrtMin "插枪保温开始时间设置-分";
CM_ SG_ 1137 ICC_PetmodeFb "宠物模式反馈信号";
CM_ SG_ 1137 ICC_SentinelModeSwitchSts "哨兵开关状态";
CM_ SG_ 1137 ICC_SentinelModeWorkingSts "哨兵工作状态
0x0: NoActive，哨兵模式未进入或未激活
0x1: Active，哨兵模式已进入或激活
0x2: LowSOC 动力电池 电量低
0x3:HVNotReady，高压系统未上电
0x4: HVFault，高压系统故障
0x5: MirrorUnFold，后视镜未展开
0x6: CameraFault，摄像头故障
0x7:LowBatVolt，蓄电池电压低";
CM_ SG_ 1137 ICC_SentinelModeFaultSts "哨兵故障状态（摄像头被遮挡）
0x0:Not Warming
0x1:Artificial occlusion摄像头被人为遮挡
0x2 :Rain and snow cover摄像头被雨雪遮挡";
CM_ SG_ 1137 ICC_SentinelModeAlarmSts "哨兵模式报警状态
0x1: Level 1待命
0x2: Level 2警惕
0x3: Level 3警报";
CM_ SG_ 1137 ICC_SentinelModeExitReason "哨兵模式异常退出原因
0x0: Normal正常
0x1:LowSOC动力电池电量低
0x2:HVNotReady高压系统未上电
0x3:HVFault高压系统故障
0x4:MirrorUnFold后视镜未展开
0x5:CameraFault，摄像头故障
0x6:LowBatVolt蓄电池电压低";
CM_ SG_ 1137 ICC_PetModeWarn "宠物模式异常关闭
0x0:Not Active
0x1:高压电池电量低
0x2:空调异常
0x3:高压异常
0x4:低压电池电量低
0x5:高压电池电量低于15%
0x6:高压电池电量低于12%
0x7:时间过长预警";
CM_ SG_ 1137 ICC_TBOXPetmodeReq "ICC发给TBOX宠物模式激活请求
0x1:ON 激活
0X2:OFF 退出";
CM_ SG_ 1137 ICC_PetModeWarn_2 "宠物模式异常关闭
0x0:Not Active
0x1:高压电池电量低
0x2:空调异常
0x3:高压异常
0x4:低压电池电量低
0x5:高压电池电量低于15%
0x6:高压电池电量低于12%
0x7:时间过长预警
0x8:车辆充电中
0x9:车辆未设防
0xA:车辆档位为非P档";
CM_ SG_ 1137 ICM_FuelLevel "燃油量";
CM_ SG_ 1137 ICM_AverageVehicleSpeed "平均车速 (仪表计算)";
CM_ SG_ 1137 ICM_DistenceToEmpty_Km "燃油续航里程";
CM_ SG_ 1137 ICM_FuelLevelFailSts "燃油故障";
CM_ SG_ 1137 ICM_Maintenance_tips "保养提示（仪表计算，可能上传到平台）";
CM_ SG_ 1137 ICM_SumTrip "小计里程";
CM_ SG_ 1144 ICC_HvBattKeepWarmSet "中控插枪保温开关";
CM_ SG_ 1144 ICC_EnergyRegSet "能量回收强度调节设置";
CM_ SG_ 1144 ICC_HvBattKeepWarmActiveReq "插枪保温开始请求";
CM_ SG_ 1210 ICC_FLSeatHeiCmd "主驾座椅高度调节";
CM_ SG_ 1210 ICC_FLSeatLvlCmd "主驾座椅水平调节";
CM_ SG_ 1210 ICC_FLSeatBackAgCmd "主驾座椅靠背角度调节";
CM_ SG_ 1210 ICC_FLSeatCushCmd "主驾座椅坐垫角度调节";
CM_ SG_ 1210 ICC_FLSeatLegSpprtCmd "主驾座椅腿托调节";
CM_ SG_ 1210 ICC_FRSeatHeiCmd "副驾座椅高度调节";
CM_ SG_ 1210 ICC_FRSeatLvlCmd "副驾座椅水平调节";
CM_ SG_ 1210 ICC_FRSeatBackAgCmd "副驾座椅靠背角度调节";
CM_ SG_ 1210 ICC_FRSeatLegSpprtCmd "副驾座椅腿托调节";
CM_ SG_ 1210 ICC_MemoryRecoveryCmd "ICC记忆保存/恢复指令";
CM_ SG_ 1210 ICC_DeleteFaceID "删除ID";
CM_ SG_ 1210 ICC_FLSeatHeitargetCmd "主驾座椅高度调节目标";
CM_ SG_ 1210 ICC_FLSeatLvltargetCmd "主驾座椅水平调节目标";
CM_ SG_ 1210 ICC_FLSeatBackAgtargetCmd "主驾座椅靠背角度调节目标";
CM_ SG_ 1210 ICC_FLSeatCushtargetCmd "主驾座椅坐垫角度调节目标";
CM_ SG_ 1210 ICC_FLSeatLegSpprttargetCmd "主驾座椅腿托调节目标";
CM_ SG_ 1210 ICC_FRSeatHeitargetCmd "副驾座椅高度调节目标";
CM_ SG_ 1210 ICC_FRSeatLvltargetCmd "副驾座椅水平调节目标";
CM_ SG_ 1210 ICC_FRSeatBackAgtargetCmd "副驾座椅靠背角度调节目标";
CM_ SG_ 1210 ICC_FRSeatLegSpprttargetCmd "副驾座椅腿托调节目标";
CM_ SG_ 1210 ICC_NapFLSeatBackAgtargetSet "小憩模式设置主驾座椅靠背角度调节目标";
CM_ SG_ 1210 ICC_NapFRSeatBackAgtargetSet "小憩模式设置副驾座椅靠背角度调节目标";
CM_ SG_ 1210 ICC_NapFLSeatLvltargetSet "小憩模式设置主驾座椅水平调节目标";
CM_ SG_ 1210 ICC_NapFRSeatLvltargetSet "小憩模式设置副驾座椅水平调节目标";
CM_ SG_ 1210 ICC_FRSeatLegRestAngleCmd "副驾座椅腿托延伸调节";
CM_ SG_ 1210 ICC_FRSeatLegRestAngletargetCmd "副驾座椅腿托延伸调节目标";
CM_ SG_ 1210 ICC_FRSeatCushCmd "副驾座椅坐垫角度调节";
CM_ SG_ 1210 ICC_FRSeatCushtargetCmd "副驾座椅坐垫角度调节目标";
CM_ SG_ 1210 ICC_FRZeroGravitySeatSw "一键副驾零压座椅开关";
CM_ SG_ 1210 ICC_HomeLinkArmHornSet "HomeLink设防鸣笛设置状态";
CM_ SG_ 1210 ICC_HomeLinkWelLightSet "HomeLink迎宾灯设置";
CM_ SG_ 1210 ICC_HomeLinkPositionSts "HomeLink 位置状态";
CM_ SG_ 1210 ICC_WelcomeOpenSetCmd "迎宾灯开启设置";
CM_ SG_ 1210 ICC_WALOpenSetCmd "远离闭锁开关设置";
CM_ SG_ 1210 ICC_UIROpenSetCmd "靠近解锁开关设置";
CM_ SG_ 1210 ICC_EnjoyableSeatSwitch "一键尊享";
CM_ SG_ 1210 ICC_BLTKeyPESet "备注：设置蓝牙钥匙的PE功能ON/OFF状态
0x0：不动作
0x1：PE功能打开
0x2：PE功能关闭";
CM_ SG_ 1210 ICC_FRMemoryDeleteCmd "副驾座椅记忆删除";
CM_ SG_ 1210 ICC_FLSitPosnlocation "主驾座椅记忆设置";
CM_ SG_ 1210 ICC_FRSitPosnlocation "副驾座椅记忆设置";
CM_ SG_ 1210 ICC_FREasyEntryExitSet "副驾便捷进入\离车";
CM_ SG_ 1210 ICC_FRMemoryRecoveryCmd "ICC副驾记忆保存/恢复指令";
CM_ SG_ 1210 ICC_ConsoleAdjustSwitch "副仪表台调节开关
0x0:Not Active
0x1:Lock
0x2:Unlock
0x3:Forward(Reserved)
0x4:Backward(Reserved)
0x5:Delpoy一键最后
0x6:Retract一键最前
0x7:Middle
0x8:Stop";
CM_ SG_ 1399 ICC_CLTC_RangeAval "CLTC工况里程(电)";
CM_ SG_ 1399 ICC_DynamicRangeAval "动态工况里程(电)";
CM_ SG_ 1399 ICC_WLTC_RangeAval "WLTC工况里程(电)";
CM_ SG_ 1399 ICC_CLTC_RangeAvalFuel "CLTC工况里程(燃油)";
CM_ SG_ 1399 ICC_WLTC_RangeAvalFuel "WLTC工况里程(燃油)";
CM_ SG_ 1399 ICC_DynamicRangeAvalFuel "动态工况里程(燃油)";
CM_ SG_ 1399 ICC_CLTC_RangeAvalComp "CLTC工况里程(综合)";
CM_ SG_ 1399 ICC_WLTC_RangeAvalComp "WLTC工况里程(综合)";
CM_ SG_ 1399 ICC_DynamicRangeAvalComp "动态工况里程(综合)";
CM_ SG_ 1399 ICC_Conditiontype "工况类型";
CM_ SG_ 1238 ICC_CFSSwitch "香氛系统开关设置";
CM_ SG_ 1238 ICC_CFSLevelSet "中控屏香氛浓度
0x0:Not_Active
0x1:Level1 淡香
0x2:Level2 清香
0x3:Level3 浓香
0x4~0x7:Reserve";
CM_ SG_ 1238 ICC_CFSPosSet "中控屏香氛类型（位置）";
CM_ SG_ 1238 ICC_PM25Switch "中控屏空气净化开关";
CM_ SG_ 1238 ICC_AQSSwitch "中控屏AQS开关";
CM_ SG_ 1238 ICC_SecSetTemp_C "二排空调温度";
CM_ SG_ 1238 ICC_SecFaceKeySts "Face Key Status
二排吹面按键开关";
CM_ SG_ 1238 ICC_SecFootKeySts "Foot Key Status
二排吹脚按键开关";
CM_ SG_ 1238 ICC_SecBlowSpeedLevelKeySts "Foot Key Status
二排吹脚按键开关";
CM_ SG_ 1238 ICC_SecAutoSwitch "二排空调AUTO开关";
CM_ SG_ 1238 ICC_SecCLMSwitch "二排空调开关";
CM_ SG_ 1238 ICC_ThrSetTemp_C "三排空调温度";
CM_ SG_ 1238 ICC_ThrFaceKeySts "Face Key Status
三排吹面按键开关";
CM_ SG_ 1238 ICC_ThrFootKeySts "Foot Key Status
三排吹脚按键开关";
CM_ SG_ 1238 ICC_ThrBlowSpeedLevelKeySts "Foot Key Status
三排吹脚按键开关";
CM_ SG_ 1238 ICC_ThrAutoSwitch "三排空调AUTO开关";
CM_ SG_ 1238 ICC_ThrCLMSwitch "三排空调开关";
CM_ SG_ 1238 ICC_ThrACRequestKeySts "Set AC Request Status
三排DVD设置AC请求开启";
CM_ SG_ 1238 ICC_DFMSwitch "单席功能开关";
CM_ SG_ 1289 ICC_TirePressureDisplayUnit "胎压显示单位";
CM_ SG_ 1289 ICC_TireTemperatureDisplayUnit "胎温显示单位";
CM_ SG_ 1289 ICC_ToggleUnits "英制单位切换";
CM_ SG_ 1289 ICC_BtConFlag "蓝牙连接状态反馈";
CM_ SG_ 1289 ICC_GPSSwitchSet "GPS定位开关设置";
CM_ SG_ 1167 ICC_KeyDriveModememory "驾驶模式记忆开关";
CM_ SG_ 1167 ICC_DriveModeSet "大屏越野模式设置
0x1：经济
0x2：标准
0x3：运动
0x4：雪/草地
0x5: 泥地
0x6: 越野
0x7: 沙地
0x8: 岩石
0x9: 专家
0xA: 智能
0xB: 涉水
0xC: 极限掉头
0xD: 漂移
0xE: 拖挂
0xF: 越野竞速";
CM_ SG_ 1167 ICC_DRIFTModeSetReq "通过大屏设置漂移模式灵敏度
0x0：不动作
0x1：入门
0x2：大师
0x3：专家";
CM_ SG_ 1167 ICC_EXPERTEIPBESPSet "关闭牵引力控制系统&车身稳定控制系统（TCS&VDC OFF）
全开（TCS、VDC等与ESP有关功能全部开启）
全关（TCS、VDC及RMI放侧翻、DTC发动机拖滞力矩管理）";
CM_ SG_ 1167 ICC_EXPERTEcoSet "专家模式动力设置柔和模式开关";
CM_ SG_ 1167 ICC_EXPERTNormSet "专家模式动力设置标准模式开关";
CM_ SG_ 1167 ICC_EXPERTSportSet "专家模式动力设置激进模式开关";
CM_ SG_ 1167 ICC_CrossaxisSet "专家模式交叉轴模式设置";
CM_ SG_ 1167 ICC_EXPERTRWDSet "专家模式驱动形式后驱设置";
CM_ SG_ 1167 ICC_EXPERTAWDSet "专家模式驱动形式四驱设置";
CM_ SG_ 1167 ICC_EXPERTAutoSet "专家模式驱动形式Auto设置";
CM_ SG_ 1167 ICC_CLIMBSet "防溜设置开关";
CM_ SG_ 1167 ICC_DriveModeExitSet "越野模式退出开关";
CM_ SG_ 1167 ICC_Confidencelevel "x模式的前端地形感知置信度（可靠度）";
CM_ SG_ 1167 ICC_V2L_IntlDisChg "放电记忆开关";
CM_ SG_ 1167 ICC_ExhibitionModeSwitch "展车模式开关";
CM_ SG_ 1167 ICC_TrailerMode "被拖模式开关";
CM_ SG_ 1167 ICC_V2L_DisChgMem "放电记忆开关";
CM_ SG_ 1167 ICC_DrivePowerDispSet "驱动系统功率显示方式开关";
CM_ SG_ 1167 ICC_WLTC_to_CLTC_Mode "驱动系统功率显示方式开关";
CM_ SG_ 1167 ICC_StopChrgnSwitch "驻车发电开关";
CM_ SG_ 1167 ICC_StopChrgnMode "驻车发电模式开关
0x1:静谧补电
0x2:快速补电";
CM_ SG_ 1167 ICC_RegenerateLevelCtrl "能量回馈设置开关
0x0:无效值
0x1:弱
0x2:强
0x3:中
0x4:单踏板";
CM_ SG_ 1167 ICC_SinglePedalMem "单踏板记忆开关";
CM_ SG_ 1167 ICC_FuelDetnSwt "燃油检测开关";
CM_ SG_ 1167 ICC_FuelDetnState "燃油检测模式状态";
CM_ SG_ 1167 ICC_FuelDetnOpDefeated "燃油检测开启失败提示";
CM_ SG_ 1167 ICC_HVDownRepairMode "断高压维修模式开关";
CM_ SG_ 1167 ICC_UTURNSnowSet "极限调头雪地场景开关";
CM_ SG_ 1167 ICC_UTURNSandSet "极限调头泥地场景开关";
CM_ SG_ 1167 ICC_UTURNMudSet "极限调头沙地场景开关";
CM_ SG_ 1167 ICC_UTURNGrassSet "极限调头草地场景开关";
CM_ SG_ 1167 ICC_LTCDispSet2 "续航里程选择开关显示";
CM_ SG_ 1326 ICC_DWDOnOff_Req "涉水雷达开关设置";
CM_ SG_ 1326 ICC_ContainerLightSet "货箱灯开关(D01P）";
CM_ SG_ 1331 ICC_RLSeatEasyEntryExitSet "二排左侧便捷进入\离车";
CM_ SG_ 1331 ICC_RRSeatEasyEntryExitSet "二排右侧便捷进入\离车";
CM_ SG_ 1331 ICC_RLMemoryRecoveryCmd "ICC二排左侧记忆保存/恢复指令";
CM_ SG_ 1331 ICC_RRMemoryRecoveryCmd "ICC二排右侧记忆保存/恢复指令";
CM_ SG_ 1331 ICC_RLSitPosnlocation "二排左侧座椅记忆设置";
CM_ SG_ 1331 ICC_RRSitPosnlocation "二排右侧座椅记忆设置";
CM_ SG_ 1331 ICC_CMSMDisplaySwitch "吸顶屏开关";
CM_ SG_ 1331 ICC_CMSMDisplayAdjustmode "吸顶屏模式调节
0x1:正常角度
0x2:观影角度";
CM_ SG_ 1331 ICC_CMSMSetstandardSwitch "吸顶屏标定开关0x1:标定打开 0x2:标定关闭";
CM_ SG_ 1331 ICC_LeftPedalControl "左边电踏请求（左边电踏软开关展开缩回请求）";
CM_ SG_ 1331 ICC_RightPedalControl "右边电踏请求（右边电踏软开关展开缩回请求）";
CM_ SG_ 1331 ICC_EPCEnable "电踏电动功能模式
0：无效值；
1：电动踏板启用（软开关启用）
2：电动踏板禁用（软开关禁用）";
CM_ SG_ 1331 ICC_AMPKTVvoiceVolumeSet "Amplifier KTV voice volume status
KTV人声音量设定";
CM_ SG_ 1331 ICC_AMPA2BENCSoundReq "Head unit ENC sound request to amplifier
ENC音源需求状态";
CM_ SG_ 1331 ICC_AMPENCVolumeSet "Amplifier ENC volume status
ENC声音量设定";
CM_ SG_ 1331 ICC_AMPA2BChimeSoundReq "Head unit Chime sound request to amplifier
Chime音源需求状态";
CM_ SG_ 1331 Set_AMPSoundFocus_2 "Amplifier sound focus status";
CM_ SG_ 1331 ICC_AMPA2BKTVvoiceSoundReq "Head unit KTV voice/IESS sound request to amplifier
KTV人声/模拟声浪音源需求状态";
CM_ SG_ 1331 ICC_MedStatusSet "冥想模式开关";
CM_ SG_ 1331 ICC_MedAreaSet "冥想模式开启区域设置";
CM_ SG_ 1331 ICC_LeftElectricPedalsSet "左电踏收回和展开软开关（前提自动打开）
0x1:踏板3D软开关开启
0x2:踏板3D软开关关闭";
CM_ SG_ 1331 ICC_RightElectricPedalsSet "右电踏收回和展开软开关（前提自动打开）
0x1:踏板3D软开关开启
0x2:踏板3D软开关关闭";
CM_ SG_ 1331 ICC_NapAreaSet2 "小憩模式开启区域设置2";
CM_ SG_ 1331 ICC_DisplayAdjustrAngReq "微信小程序遥控器控制吸顶屏角度90-110";
CM_ SG_ 1331 ICC_CMSMTouchSts "吸顶屏触摸信号0x1:有触摸 0x2:无触摸";
CM_ SG_ 1333 ICC_SRFCmd "天窗开关设置
全开
全关
翘起";
CM_ SG_ 1333 ICC_SRFPercentCmd "手滑动开启天窗百分比";
CM_ SG_ 1333 ICC_CSunshadeReq "天幕遮阳帘开关设置";
CM_ SG_ 1333 ICC_CSunshadePercentReq "手滑动开启天幕遮阳帘百分比";
CM_ SG_ 1333 ICC_SunshadeCmd "遮阳帘开关设置
全开
全关
一半";
CM_ SG_ 1333 ICC_SunshadePercentCmd "手滑动开启遮阳帘百分比";
CM_ SG_ 1335 ICC_SET_EPS_SteerReturnRmdSts "方向盘回正开关";
CM_ SG_ 1335 ICC_SET_MFSShake "方向盘震动开关";
CM_ SG_ 1335 ICC_DMS_1_DistractionLevel "方向盘震动等级调节";
CM_ SG_ 1335 ICC_OverLoadWarnShieldSet "重量报警屏蔽软开关";
CM_ SG_ 1335 ICC_BSWReq "智能擦盘开启信号";
CM_ SG_ 1335 ICC_horizontalReq "露营找平软开关";
CM_ SG_ 1337 ICC_SET_BT_ReduceWindSpeed "大屏设置蓝牙通话降低风速";
CM_ SG_ 1337 ICC_SET_IPM_FirstBlowing "夏日热风规避_大屏设置空调启动时第一口风";
CM_ SG_ 1337 ICC_SET_IPM_BlowerDelay "大屏设置车辆熄火空调鼓风机延时";
CM_ SG_ 1337 ICC_SET_CirculationInTunnels "大屏设置隧道内循环";
CM_ SG_ 1337 ICC_UVCLuminanceReq "大屏设置紫外线杀菌灯强度请求";
CM_ SG_ 1337 ICC_UVCControlReq "大屏设置紫外线杀菌灯";
CM_ SG_ 1337 ICC_CrossCountryCoolingReq "越野散热开关";
CM_ SG_ 1337 ICC_KeepWarmReq "恒温模式状态开关请求";
CM_ SG_ 1337 ICC_keepwarmSetTemperatureReq "恒温模式温度设置请求";
CM_ SG_ 1337 ICC_ParkingAirConditioning "驻车空调使能开关
ventilate通风";
CM_ SG_ 1337 ICC_CoolantFill_Req "冷却液加注开关请求";
CM_ SG_ 1337 ICC_FraganceLightoffReq "香氛氛围灯开关状态";
CM_ SG_ 1337 ICC_FraganceMemoffReq "香氛记忆开关状态";
CM_ SG_ 1337 ICC_AirPurgeReminderReq "空气净化提醒开关请求";
CM_ SG_ 1337 ICC_BiochemicalFuncReq "大屏生化功能开关";
CM_ SG_ 1337 ICC_TimedVentilationReq "大屏定时换气功能开关";
CM_ SG_ 1337 ICC_PetmodeSetTemperature_L_C "宠物模式前左空调温度设置";
CM_ SG_ 1337 ICC_PetModeSetTemperature_R_C "宠物模式前右空调温度设置";
CM_ SG_ 1337 ICC_PetModeSetCLMOn "宠物模式空调开关设置";
CM_ SG_ 1337 ICC_PetModeSetAutoKeySts "宠物模式空调自动模式设置";
CM_ SG_ 1337 ICC_PetModeSetCirculationSts "宠物模式空调内外循环切换设置";
CM_ SG_ 1318 ICC_SET_TDL_Rhythm_Switch "氛围灯律动开关";
CM_ SG_ 1318 ICC_SET_TDL_Switch "氛围灯开关";
CM_ SG_ 1318 ICC_SET_TDL_ColourModeAdj "氛围灯颜色模式调节

Monochrome_单色
panchromatic为全色
FLZCU_TDL";
CM_ SG_ 1318 ICC_VoiceWake "语音唤醒";
CM_ SG_ 1318 ICC_TDL_RhythmReq "音乐律动模式调节";
CM_ SG_ 1318 ICC_SET_ApiluminanceAdj "氛围灯亮度调节
氛围灯亮度_Level1最暗_Level8最亮FLZCU_TDL";
CM_ SG_ 1318 ICC_SET_MusicLoudness_120HZ "均衡器设置";
CM_ SG_ 1318 ICC_SET_MusicLoudness_250HZ "均衡器设置";
CM_ SG_ 1318 ICC_SET_MusicLoudness_500HZ "均衡器设置";
CM_ SG_ 1318 ICC_SET_MusicLoudness_1000HZ "均衡器设置";
CM_ SG_ 1318 ICC_SET_MusicLoudness_1500HZ "均衡器设置";
CM_ SG_ 1318 ICC_SET_MusicLoudness_2000HZ "均衡器设置";
CM_ SG_ 1318 ICC_SET_MusicLoudness_6000HZ "均衡器设置";
CM_ SG_ 1318 ICC_TDL_FlowLightSw "流水灯开关";
CM_ SG_ 1318 ICC_TDL_FlowLightModeAdj "流水灯模式调节";
CM_ SG_ 1318 ICC_SET_256ColourAdj "多元颜色设置（256色）";
CM_ SG_ 1320 ICC_Chb_Req "冰箱开关请求";
CM_ SG_ 1320 ICC_ChbMem_Req "记忆开关请求";
CM_ SG_ 1320 ICC_ChbDelay_Req "延时开关请求";
CM_ SG_ 1320 ICC_ChbSterilization_Req "杀菌开关请求";
CM_ SG_ 1320 ICC_ChbItemsLeft_Req "物品遗留开关请求";
CM_ SG_ 1320 ICC_ParkingRadarSwSet "驻车雷达开关请求";
CM_ SG_ 1320 ICC_ChbTimeset_Req "延时时间设置请求";
CM_ SG_ 1320 ICC_ChbCoolset_Req "制冷温度设置
0x1~0xD:-6℃~6℃（捷途使用）
0xE~0x19:-18℃~-7℃（股份使用，捷途预留）";
CM_ SG_ 1320 ICC_ChbCoolorheat_Req "制冷制热开关请求";
CM_ SG_ 1320 ICC_ChbHeatset_Req "制热温度调节设置请求";
CM_ SG_ 1360 ICC_LISD_DisplaySwitch "自定义图片实时显示功能开关";
CM_ SG_ 1360 ICC_LISD_ParkingShowCMD "驻车动画开关（反馈已有）";
CM_ SG_ 1360 ICC_RoofCampLampSetL "左侧露营射灯软开关（选装）";
CM_ SG_ 1360 ICC_RISD_DisplaySwitch "自定义图片实时显示功能开关";
CM_ SG_ 1360 ICC_RISD_ParkingShowCMD "驻车动画开关（反馈已有）";
CM_ SG_ 1360 ICC_RoofCampLampSetR "右侧露营射灯软开关（选装）";
CM_ SG_ 1360 ICC_LogoParkingReq "前LOGO驻车点亮开关请求";
CM_ SG_ 1360 ICC_LogoChargingReq "前LOGO充电灯效开关请求";
CM_ SG_ 1360 ICC_DRLSw "日间行车灯软开关";
CM_ SG_ 1360 ICC_TopLightSet "车顶射灯软开关（选装）";
CM_ SG_ 1360 ICC_APillarYellowAmbientSet "A柱黄色氛围灯软开关（选装）";
CM_ SG_ 1360 ICC_APillarWhiteAmbientSet "A柱白色氛围灯软开关（选装）";
CM_ SG_ 1360 ICC_LISD_ParkingShowMod "LISD驻车动画模式";
CM_ SG_ 1360 ICC_RISD_ParkingShowMod "RISD驻车动画模式";
CM_ SG_ 1360 ICC_APillarSpotLampSet "A柱射灯软开关（选装）";
CM_ SG_ 1360 ICC_PenetrationLampSetF "前贯穿灯软开关(D01P使用)";
CM_ SG_ 1360 ICC_MusicLampShowSW "0x0: 灯光秀总开关关闭
0x1: 灯光秀总开关开启";
CM_ SG_ 1360 ICC_LogoColorReq "Logo灯颜色设置，1-256分别对应256种颜色";
CM_ SG_ 1360 ICC_XDriveMode "ICC通过视频流发给VCU进行驾驶模式设置
0x0:Not Active
0x1:无法判断 unidentifiable
0x2:普通1 Normal
0x3:雪地1 SNOW
0x4:泥地1 MUD
0x5:岩石1 ROCK
0x6:沙地1 SAND
0x7:水面1 WATER SURFACE
0x8：普通2 Normal
0x9:雪地2 SNOW
0xA:泥地2 MUD
0xB: 岩石2 ROCK
0xC:沙地2 SAND
0xD:水面2 WATER SURFACE
0xE:普通3 Normal
0xF:雪地3 SNOW
0x10:泥地3 MUD
0x11:岩石3 ROCK
0x12:沙地3 SAND";
BA_DEF_ BO_  "GenMsgCycleTimeFast" INT 0 50000;
BA_DEF_ BO_  "GenMsgNrOfRepetition" INT 0 999999;
BA_DEF_ BO_  "GenMsgDelayTime" INT 0 1000;
BA_DEF_ BO_  "VFrameFormat" ENUM  "StandardCAN","ExtendedCAN","reserved","reserved","reserved","reserved","reserved","reserved","reserved","reserved","reserved","reserved","reserved","reserved","StandardCAN_FD","ExtendedCAN_FD";
BA_DEF_ BO_  "GenMsgILSupport" ENUM  "No","Yes";
BA_DEF_ BO_  "NmMessage" ENUM  "No","Yes";
BA_DEF_ BO_  "GenMsgSendType" ENUM  "Cycle","Event","IfActive","CE","CA","NoMsgSendType";
BA_DEF_ BO_  "GenMsgCycleTime" INT 0 50000;
BA_DEF_ BO_  "CANFD_BRS" INT 0 1;
BA_DEF_ BO_  "NmAsrMessage" ENUM  "No","Yes";
BA_DEF_ BO_  "GRC_ASIL" ENUM  "vector_leerstring","QM","A","B","C","D";
BA_DEF_ BO_  "GRC_History" STRING ;
BA_DEF_ SG_  "GenSigStartValue" FLOAT 0 100000000000;
BA_DEF_ SG_  "GenSigInactiveValue" INT 0 100000;
BA_DEF_ SG_  "GenSigInvalidValue" INT 0 100000;
BA_DEF_ SG_  "GenSigSendType" ENUM  "Cycle","OnChange","OnWrite","IfActive","OnChangeWithRepetition","OnWriteWithRepetition","IfActiveWithRepetition","NoSigSendType","OnChangeAndIfActive","OnChangeAndIfActiveWithRepetition","CA","CE","Event";
BA_DEF_ SG_  "GRC_Sig_ASIL" ENUM  "vector_leerstring","QM","A","B","C","D";
BA_DEF_ SG_  "E2EDataId" INT 0 0;
BA_DEF_ SG_  "E2EProfile" STRING ;
BA_DEF_ SG_  "E2EDataLength" INT 0 512;
BA_DEF_DEF_  "GenMsgCycleTimeFast" 0;
BA_DEF_DEF_  "GenMsgNrOfRepetition" 0;
BA_DEF_DEF_  "GenMsgDelayTime" 0;
BA_DEF_DEF_  "VFrameFormat" "StandardCAN";
BA_DEF_DEF_  "GenMsgILSupport" "No";
BA_DEF_DEF_  "NmMessage" "No";
BA_DEF_DEF_  "GenMsgSendType" "NoMsgSendType";
BA_DEF_DEF_  "GenMsgCycleTime" 0;
BA_DEF_DEF_  "CANFD_BRS" 0;
BA_DEF_DEF_  "NmAsrMessage" "No";
BA_DEF_DEF_  "GRC_ASIL" "";
BA_DEF_DEF_  "GRC_History" "";
BA_DEF_DEF_  "GenSigStartValue" 0;
BA_DEF_DEF_  "GenSigInactiveValue" 0;
BA_DEF_DEF_  "GenSigInvalidValue" 0;
BA_DEF_DEF_  "GenSigSendType" "NoSigSendType";
BA_DEF_DEF_  "GRC_Sig_ASIL" "";
BA_DEF_DEF_  "E2EDataId" 0;
BA_DEF_DEF_  "E2EProfile" "";
BA_DEF_DEF_  "E2EDataLength" 0;
BA_ "CANFD_BRS" BO_ 1265 1;
BA_ "GenMsgSendType" BO_ 1265 3;
BA_ "GenMsgCycleTime" BO_ 1265 100;
BA_ "GenMsgCycleTimeFast" BO_ 1265 100;
BA_ "GenMsgNrOfRepetition" BO_ 1265 2;
BA_ "GenMsgDelayTime" BO_ 1265 5;
BA_ "GenMsgILSupport" BO_ 1265 1;
BA_ "VFrameFormat" BO_ 1265 14;
BA_ "CANFD_BRS" BO_ 1137 1;
BA_ "GenMsgSendType" BO_ 1137 3;
BA_ "GenMsgCycleTime" BO_ 1137 100;
BA_ "GenMsgCycleTimeFast" BO_ 1137 100;
BA_ "GenMsgNrOfRepetition" BO_ 1137 2;
BA_ "GenMsgDelayTime" BO_ 1137 5;
BA_ "GenMsgILSupport" BO_ 1137 1;
BA_ "GRC_History" BO_ 1137 "[{'approvedBy':'贾少辉','author':'吴慧','changesComments':'（同步D01主项目V2.3.1版本更新）刘标ICC需求，ICC_KeepWarmStrtHour新增无效值0x1F，ICC_KeepWarmStrtMin新增无效值0x3F','date':'2025/5/6','ecu':'ICC_TBOX_27(0x471)','ecuName':'FLZCU,HCU,ICC','reviewed";
BA_ "VFrameFormat" BO_ 1137 14;
BA_ "CANFD_BRS" BO_ 1144 1;
BA_ "GenMsgSendType" BO_ 1144 0;
BA_ "GenMsgCycleTime" BO_ 1144 100;
BA_ "GenMsgCycleTimeFast" BO_ 1144 100;
BA_ "GenMsgNrOfRepetition" BO_ 1144 2;
BA_ "GenMsgDelayTime" BO_ 1144 5;
BA_ "GenMsgILSupport" BO_ 1144 1;
BA_ "VFrameFormat" BO_ 1144 14;
BA_ "CANFD_BRS" BO_ 1210 1;
BA_ "GenMsgSendType" BO_ 1210 3;
BA_ "GenMsgCycleTime" BO_ 1210 100;
BA_ "GenMsgCycleTimeFast" BO_ 1210 100;
BA_ "GenMsgNrOfRepetition" BO_ 1210 2;
BA_ "GenMsgDelayTime" BO_ 1210 5;
BA_ "GenMsgILSupport" BO_ 1210 1;
BA_ "VFrameFormat" BO_ 1210 14;
BA_ "CANFD_BRS" BO_ 1399 1;
BA_ "GenMsgSendType" BO_ 1399 0;
BA_ "GenMsgCycleTime" BO_ 1399 1000;
BA_ "GenMsgILSupport" BO_ 1399 1;
BA_ "VFrameFormat" BO_ 1399 14;
BA_ "CANFD_BRS" BO_ 1238 1;
BA_ "GenMsgSendType" BO_ 1238 0;
BA_ "GenMsgCycleTime" BO_ 1238 100;
BA_ "GenMsgCycleTimeFast" BO_ 1238 50;
BA_ "GenMsgNrOfRepetition" BO_ 1238 2;
BA_ "GenMsgDelayTime" BO_ 1238 5;
BA_ "GenMsgILSupport" BO_ 1238 1;
BA_ "VFrameFormat" BO_ 1238 14;
BA_ "CANFD_BRS" BO_ 1289 1;
BA_ "GenMsgSendType" BO_ 1289 0;
BA_ "GenMsgCycleTime" BO_ 1289 500;
BA_ "GenMsgILSupport" BO_ 1289 1;
BA_ "GRC_History" BO_ 1289 "[{'approvedBy':'贾少辉','author':'吴慧','changesComments':'刘标ICC新增发送：GPS定位开启和关闭设置ICC_GPSSwitchSet信号，TBOX接收','date':'2025/3/24','ecu':'ICC_34(0x509)','ecuName':'ICC','reviewedBy':'杨华','revision':'V2.3'}]";
BA_ "VFrameFormat" BO_ 1289 14;
BA_ "CANFD_BRS" BO_ 1167 1;
BA_ "GenMsgSendType" BO_ 1167 1;
BA_ "GenMsgCycleTimeFast" BO_ 1167 50;
BA_ "GenMsgNrOfRepetition" BO_ 1167 2;
BA_ "GenMsgDelayTime" BO_ 1167 5;
BA_ "GenMsgILSupport" BO_ 1167 1;
BA_ "GRC_History" BO_ 1167 "[{'approvedBy':'贾少辉','author':'吴慧','changesComments':'刘标ICC_XDriveMode信号需求周期帧发送，当前报文为事件帧，不满足需求，故删除该信号，在0x550新增。','date':'2025/5/15','ecu':'ICC_35(0x48F)','ecuName':'ICC,FLZCU,HCU','reviewedBy':'杨华','revision':";
BA_ "VFrameFormat" BO_ 1167 14;
BA_ "CANFD_BRS" BO_ 1326 1;
BA_ "GenMsgSendType" BO_ 1326 1;
BA_ "GenMsgCycleTimeFast" BO_ 1326 100;
BA_ "GenMsgNrOfRepetition" BO_ 1326 2;
BA_ "GenMsgDelayTime" BO_ 1326 5;
BA_ "GenMsgILSupport" BO_ 1326 1;
BA_ "VFrameFormat" BO_ 1326 14;
BA_ "CANFD_BRS" BO_ 1331 1;
BA_ "GenMsgSendType" BO_ 1331 1;
BA_ "GenMsgCycleTimeFast" BO_ 1331 100;
BA_ "GenMsgNrOfRepetition" BO_ 1331 2;
BA_ "GenMsgDelayTime" BO_ 1331 5;
BA_ "GenMsgILSupport" BO_ 1331 1;
BA_ "GRC_History" BO_ 1331 "[{'approvedBy':'贾少辉','author':'吴慧','changesComments':'（同步D01主项目V2.3.1版本更新）魏睿ICC新增发送ICC_CMSMTouchSts信号，CMSM接收无反馈信号，吸顶屏触摸防夹','date':'2025/5/6','ecu':'ICC_IC_37(0x533)','ecuName':'ICC,CMSM','reviewedBy':'杨华','revisi";
BA_ "VFrameFormat" BO_ 1331 14;
BA_ "CANFD_BRS" BO_ 1333 1;
BA_ "GenMsgSendType" BO_ 1333 1;
BA_ "GenMsgCycleTimeFast" BO_ 1333 100;
BA_ "GenMsgNrOfRepetition" BO_ 1333 2;
BA_ "GenMsgDelayTime" BO_ 1333 5;
BA_ "GenMsgILSupport" BO_ 1333 1;
BA_ "VFrameFormat" BO_ 1333 14;
BA_ "CANFD_BRS" BO_ 1335 1;
BA_ "GenMsgSendType" BO_ 1335 0;
BA_ "GenMsgCycleTime" BO_ 1335 100;
BA_ "GenMsgCycleTimeFast" BO_ 1335 20;
BA_ "GenMsgNrOfRepetition" BO_ 1335 2;
BA_ "GenMsgDelayTime" BO_ 1335 5;
BA_ "GenMsgILSupport" BO_ 1335 1;
BA_ "VFrameFormat" BO_ 1335 14;
BA_ "CANFD_BRS" BO_ 1337 1;
BA_ "GenMsgSendType" BO_ 1337 1;
BA_ "GenMsgCycleTimeFast" BO_ 1337 100;
BA_ "GenMsgNrOfRepetition" BO_ 1337 2;
BA_ "GenMsgDelayTime" BO_ 1337 5;
BA_ "GenMsgILSupport" BO_ 1337 1;
BA_ "GRC_History" BO_ 1337 "[{'approvedBy':'贾少辉','author':'吴慧','changesComments':'刘标ICC新增发送ICC_BiochemicalFuncReq大屏生化功能开关，ICC_TimedVentilationReq大屏定时换气功能开关，TMS接收（信号bit位60-53被T1J FL2华为智驾版占用）','date':'2025/3/13','ecu':'ICC_TMS_40(0x539)',";
BA_ "VFrameFormat" BO_ 1337 14;
BA_ "CANFD_BRS" BO_ 1318 1;
BA_ "GenMsgSendType" BO_ 1318 3;
BA_ "GenMsgCycleTime" BO_ 1318 100;
BA_ "GenMsgCycleTimeFast" BO_ 1318 100;
BA_ "GenMsgNrOfRepetition" BO_ 1318 2;
BA_ "GenMsgDelayTime" BO_ 1318 5;
BA_ "GenMsgILSupport" BO_ 1318 1;
BA_ "GRC_History" BO_ 1318 "[{'approvedBy':'贾少辉','author':'吴慧','changesComments':'刘标ICC需求修改，ICC_SET_256ColourAdj初始值由0x1改为0xA，无效值填写为0x7F，对应实际色号','date':'2025/3/4','ecu':'ICC_TDL_41(0x526)','ecuName':'ICC,FLZCU','reviewedBy':'杨华','revision':'V2.3'}]";
BA_ "VFrameFormat" BO_ 1318 14;
BA_ "CANFD_BRS" BO_ 1320 1;
BA_ "GenMsgSendType" BO_ 1320 1;
BA_ "GenMsgCycleTimeFast" BO_ 1320 100;
BA_ "GenMsgNrOfRepetition" BO_ 1320 2;
BA_ "GenMsgDelayTime" BO_ 1320 5;
BA_ "GenMsgILSupport" BO_ 1320 1;
BA_ "VFrameFormat" BO_ 1320 14;
BA_ "CANFD_BRS" BO_ 1360 1;
BA_ "GenMsgSendType" BO_ 1360 0;
BA_ "GenMsgCycleTime" BO_ 1360 100;
BA_ "GenMsgCycleTimeFast" BO_ 1360 100;
BA_ "GenMsgNrOfRepetition" BO_ 1360 2;
BA_ "GenMsgDelayTime" BO_ 1360 5;
BA_ "GenMsgILSupport" BO_ 1360 1;
BA_ "GRC_History" BO_ 1360 "[{'approvedBy':'贾少辉','author':'吴慧','changesComments':'刘标新增ICC_XDriveMode信号，剪切0x48F信号，将信号发送类型改为cycle，同步需将LSB改为52bit。','date':'2025/5/15','ecu':'ICC_LC_42(0x550)','ecuName':'ICC,FLZCU,HCU','reviewedBy':'杨华','revision':'V";
BA_ "VFrameFormat" BO_ 1360 14;
BA_ "GenSigSendType" SG_ 1265 ICC_PwrOff 0;
BA_ "GenSigSendType" SG_ 1265 ICC_EtmEgySave 0;
BA_ "GenSigSendType" SG_ 1265 ICC_HoodSW 5;
BA_ "GenSigSendType" SG_ 1265 ICC_GloveboxSW 5;
BA_ "GenSigSendType" SG_ 1265 ICC_ChrgPortCover_Switch 5;
BA_ "GenSigSendType" SG_ 1265 ICC_ReWinDefrstSwt 5;
BA_ "GenSigSendType" SG_ 1265 ICC_RearMirrorFoldCmd 5;
BA_ "GenSigSendType" SG_ 1265 ICC_CenterLockSwt 5;
BA_ "GenSigSendType" SG_ 1265 ICC_ReverseExtMirrorSts 5;
BA_ "GenSigSendType" SG_ 1265 ICC_LightMainSwitchSts 5;
BA_ "GenSigSendType" SG_ 1265 ICC_AutoFoldSts 5;
BA_ "GenSigSendType" SG_ 1265 ICC_HeadlampHeightSts 5;
BA_ "GenSigSendType" SG_ 1265 ICC_WiprSnvty 5;
BA_ "GenSigSendType" SG_ 1265 ICC_WindowCmd 5;
BA_ "GenSigSendType" SG_ 1265 ICC_LowBeamDelayOff 5;
BA_ "GenSigSendType" SG_ 1265 ICC_FLWinCmd 5;
BA_ "GenSigInvalidValue" SG_ 1265 ICC_FLWinCmd 127;
BA_ "GenSigSendType" SG_ 1265 ICC_FRWinCmd 5;
BA_ "GenSigInvalidValue" SG_ 1265 ICC_FRWinCmd 127;
BA_ "GenSigSendType" SG_ 1265 ICC_RLWinCmd 5;
BA_ "GenSigInvalidValue" SG_ 1265 ICC_RLWinCmd 127;
BA_ "GenSigSendType" SG_ 1265 ICC_RRWinCmd 5;
BA_ "GenSigInvalidValue" SG_ 1265 ICC_RRWinCmd 127;
BA_ "GenSigSendType" SG_ 1265 ICC_FGHeatSts 4;
BA_ "GenSigSendType" SG_ 1265 ICC_AutolockSts 5;
BA_ "GenSigSendType" SG_ 1265 ICC_WiperID 5;
BA_ "GenSigSendType" SG_ 1265 ICC_MaintenanceMode 5;
BA_ "GenSigSendType" SG_ 1265 ICC_lockSetSwitchSts 5;
BA_ "GenSigSendType" SG_ 1265 ICC_ChildLockSW 5;
BA_ "GenSigSendType" SG_ 1265 ICC_ParkUnlockEnable 5;
BA_ "GenSigSendType" SG_ 1265 ICC_BLEOpenDriverDoorEnable 5;
BA_ "GenSigSendType" SG_ 1265 ICC_WinInhbSwt 5;
BA_ "GenSigSendType" SG_ 1265 ICC_SteerWhlHeatgSwt 5;
BA_ "GenSigSendType" SG_ 1265 ICC_AutoHeatingset 5;
BA_ "GenSigSendType" SG_ 1265 ICC_FrontFogSw 5;
BA_ "GenSigSendType" SG_ 1265 ICC_RearFogSw 5;
BA_ "GenSigSendType" SG_ 1265 ICC_DoorControlSW 5;
BA_ "GenSigSendType" SG_ 1265 ICC_LockCarWinCloseSw 5;
BA_ "GenSigSendType" SG_ 1265 ICC_RainCarWinCloseSw 5;
BA_ "GenSigSendType" SG_ 1265 ICC_EasyEntryExitSet 5;
BA_ "GenSigSendType" SG_ 1265 ICC_NapTimeSet 5;
BA_ "GenSigSendType" SG_ 1265 ICC_NapAreaSet 5;
BA_ "GenSigSendType" SG_ 1265 ICC_NapStatusSet 5;
BA_ "GenSigSendType" SG_ 1265 ICC_NapCFSStatusSet 5;
BA_ "GenSigSendType" SG_ 1265 ICC_NapSetTemperature 5;
BA_ "GenSigInvalidValue" SG_ 1265 ICC_NapSetTemperature 31;
BA_ "GenSigStartValue" SG_ 1265 ICC_NapSetTemperature 31;
BA_ "GenSigSendType" SG_ 1265 ICC_SpoilerWelcomeFunSet 5;
BA_ "GenSigSendType" SG_ 1265 ICC_SpoilerCtrlCmd 5;
BA_ "GenSigSendType" SG_ 1265 ICC_HazardLightReq 0;
BA_ "GenSigSendType" SG_ 1265 ICC_MusicStatus 0;
BA_ "GenSigSendType" SG_ 1265 ICC_CinemaStatus 0;
BA_ "GenSigSendType" SG_ 1137 ICC_ElectronicFenceStsFed_471h 0;
BA_ "GenSigSendType" SG_ 1137 ICC_GPSSailingSpeed_471h 0;
BA_ "GenSigSendType" SG_ 1137 ICC_BookChrgSetReq 5;
BA_ "GenSigStartValue" SG_ 1137 ICC_BookChrgSetReq 3;
BA_ "GenSigSendType" SG_ 1137 ICC_BkChrgStartTimeYear 0;
BA_ "GenSigSendType" SG_ 1137 ICC_BkChrgStartTimeDay 0;
BA_ "GenSigStartValue" SG_ 1137 ICC_BkChrgStartTimeDay 1;
BA_ "GenSigSendType" SG_ 1137 ICC_BkChrgStartTimeHour 0;
BA_ "GenSigInvalidValue" SG_ 1137 ICC_BkChrgStartTimeHour 31;
BA_ "GenSigStartValue" SG_ 1137 ICC_BkChrgStartTimeHour 31;
BA_ "GenSigSendType" SG_ 1137 ICC_BkChrgStartTimemMin 0;
BA_ "GenSigInvalidValue" SG_ 1137 ICC_BkChrgStartTimemMin 63;
BA_ "GenSigStartValue" SG_ 1137 ICC_BkChrgStartTimemMin 63;
BA_ "GenSigSendType" SG_ 1137 ICC_BkChrgStartTimeMonth 0;
BA_ "GenSigStartValue" SG_ 1137 ICC_BkChrgStartTimeMonth 1;
BA_ "GenSigSendType" SG_ 1137 ICC_BkChrgDuration 0;
BA_ "GenSigInvalidValue" SG_ 1137 ICC_BkChrgDuration 2047;
BA_ "GenSigStartValue" SG_ 1137 ICC_BkChrgDuration 2047;
BA_ "GenSigSendType" SG_ 1137 ICC_BkChrgCycleType 0;
BA_ "GenSigSendType" SG_ 1137 ICC_StopChrgReq 5;
BA_ "GenSigSendType" SG_ 1137 ICC_BkChrgCycleMon 0;
BA_ "GenSigSendType" SG_ 1137 ICC_BkChrgCycleTues 0;
BA_ "GenSigSendType" SG_ 1137 ICC_BkChrgCycleWen 0;
BA_ "GenSigSendType" SG_ 1137 ICC_BkChrgCycleThur 0;
BA_ "GenSigSendType" SG_ 1137 ICC_BkChrgCycleFri 0;
BA_ "GenSigSendType" SG_ 1137 ICC_BkChrgCycleSat 0;
BA_ "GenSigSendType" SG_ 1137 ICC_BkChrgCycleSun 0;
BA_ "GenSigSendType" SG_ 1137 ICC_KeepWarmStrt 0;
BA_ "GenSigStartValue" SG_ 1137 ICC_KeepWarmStrt 1;
BA_ "GenSigSendType" SG_ 1137 ICC_KeepWarmStrtHour 0;
BA_ "GenSigInvalidValue" SG_ 1137 ICC_KeepWarmStrtHour 31;
BA_ "GenSigSendType" SG_ 1137 ICC_KeepWarmStrtMin 0;
BA_ "GenSigInvalidValue" SG_ 1137 ICC_KeepWarmStrtMin 63;
BA_ "GenSigSendType" SG_ 1137 ICC_PetmodeFb 0;
BA_ "GenSigInvalidValue" SG_ 1137 ICC_PetmodeFb 3;
BA_ "GenSigSendType" SG_ 1137 ICC_SentinelModeSwitchSts 0;
BA_ "GenSigSendType" SG_ 1137 ICC_SentinelModeWorkingSts 0;
BA_ "GenSigSendType" SG_ 1137 ICC_SentinelModeFaultSts 0;
BA_ "GenSigSendType" SG_ 1137 ICC_SentinelModeAlarmSts 0;
BA_ "GenSigSendType" SG_ 1137 ICC_SentinelModeExitReason 0;
BA_ "GenSigSendType" SG_ 1137 ICC_PetModeWarn 0;
BA_ "GenSigSendType" SG_ 1137 ICC_TBOXPetmodeReq 5;
BA_ "GenSigSendType" SG_ 1137 ICC_PetModeWarn_2 0;
BA_ "GenSigSendType" SG_ 1137 ICM_FuelLevel 0;
BA_ "GenSigSendType" SG_ 1137 ICM_AverageVehicleSpeed 0;
BA_ "GenSigSendType" SG_ 1137 ICM_DistenceToEmpty_Km 0;
BA_ "GenSigSendType" SG_ 1137 ICM_FuelLevelFailSts 0;
BA_ "GenSigSendType" SG_ 1137 ICM_Maintenance_tips 0;
BA_ "GenSigSendType" SG_ 1137 ICM_SumTrip 0;
BA_ "GenSigSendType" SG_ 1144 ICC_CarSickRelfModeReq 5;
BA_ "GenSigSendType" SG_ 1144 ICC_HvBattKeepWarmSet 0;
BA_ "GenSigInvalidValue" SG_ 1144 ICC_HvBattKeepWarmSet 3;
BA_ "GenSigStartValue" SG_ 1144 ICC_HvBattKeepWarmSet 3;
BA_ "GenSigSendType" SG_ 1144 ICC_EnergyRegSet 5;
BA_ "GenSigSendType" SG_ 1144 ICC_HvBattKeepWarmActiveReq 5;
BA_ "GenSigSendType" SG_ 1210 ICC_1_IDverify 5;
BA_ "GenSigSendType" SG_ 1210 ICC_FLSeatHeiCmd 5;
BA_ "GenSigSendType" SG_ 1210 ICC_FLSeatLvlCmd 5;
BA_ "GenSigSendType" SG_ 1210 ICC_FLSeatBackAgCmd 5;
BA_ "GenSigSendType" SG_ 1210 ICC_FLSeatCushCmd 5;
BA_ "GenSigSendType" SG_ 1210 ICC_FLSeatLegSpprtCmd 5;
BA_ "GenSigSendType" SG_ 1210 ICC_FRSeatHeiCmd 5;
BA_ "GenSigSendType" SG_ 1210 ICC_FRSeatLvlCmd 5;
BA_ "GenSigSendType" SG_ 1210 ICC_FRSeatBackAgCmd 5;
BA_ "GenSigSendType" SG_ 1210 ICC_FRSeatLegSpprtCmd 5;
BA_ "GenSigSendType" SG_ 1210 ICC_MemoryRecoveryCmd 5;
BA_ "GenSigSendType" SG_ 1210 ICC_DeleteFaceID 5;
BA_ "GenSigSendType" SG_ 1210 ICC_FLSeatHeitargetCmd 5;
BA_ "GenSigInvalidValue" SG_ 1210 ICC_FLSeatHeitargetCmd 127;
BA_ "GenSigSendType" SG_ 1210 ICC_FLSeatLvltargetCmd 5;
BA_ "GenSigInvalidValue" SG_ 1210 ICC_FLSeatLvltargetCmd 127;
BA_ "GenSigSendType" SG_ 1210 ICC_FLSeatBackAgtargetCmd 5;
BA_ "GenSigInvalidValue" SG_ 1210 ICC_FLSeatBackAgtargetCmd 127;
BA_ "GenSigSendType" SG_ 1210 ICC_FLSeatCushtargetCmd 5;
BA_ "GenSigInvalidValue" SG_ 1210 ICC_FLSeatCushtargetCmd 127;
BA_ "GenSigSendType" SG_ 1210 ICC_FLSeatLegSpprttargetCmd 5;
BA_ "GenSigInvalidValue" SG_ 1210 ICC_FLSeatLegSpprttargetCmd 127;
BA_ "GenSigSendType" SG_ 1210 ICC_FRSeatHeitargetCmd 5;
BA_ "GenSigInvalidValue" SG_ 1210 ICC_FRSeatHeitargetCmd 127;
BA_ "GenSigSendType" SG_ 1210 ICC_FRSeatLvltargetCmd 5;
BA_ "GenSigInvalidValue" SG_ 1210 ICC_FRSeatLvltargetCmd 127;
BA_ "GenSigSendType" SG_ 1210 ICC_FRSeatBackAgtargetCmd 5;
BA_ "GenSigInvalidValue" SG_ 1210 ICC_FRSeatBackAgtargetCmd 127;
BA_ "GenSigSendType" SG_ 1210 ICC_FRSeatLegSpprttargetCmd 5;
BA_ "GenSigInvalidValue" SG_ 1210 ICC_FRSeatLegSpprttargetCmd 127;
BA_ "GenSigSendType" SG_ 1210 ICC_NapFLSeatBackAgtargetSet 5;
BA_ "GenSigInvalidValue" SG_ 1210 ICC_NapFLSeatBackAgtargetSet 127;
BA_ "GenSigSendType" SG_ 1210 ICC_NapFRSeatBackAgtargetSet 5;
BA_ "GenSigInvalidValue" SG_ 1210 ICC_NapFRSeatBackAgtargetSet 127;
BA_ "GenSigSendType" SG_ 1210 ICC_NapFLSeatLvltargetSet 5;
BA_ "GenSigInvalidValue" SG_ 1210 ICC_NapFLSeatLvltargetSet 127;
BA_ "GenSigSendType" SG_ 1210 ICC_NapFRSeatLvltargetSet 5;
BA_ "GenSigInvalidValue" SG_ 1210 ICC_NapFRSeatLvltargetSet 127;
BA_ "GenSigSendType" SG_ 1210 ICC_FRSeatLegRestAngleCmd 5;
BA_ "GenSigSendType" SG_ 1210 ICC_FRSeatLegRestAngletargetCmd 5;
BA_ "GenSigInvalidValue" SG_ 1210 ICC_FRSeatLegRestAngletargetCmd 127;
BA_ "GenSigSendType" SG_ 1210 ICC_FRSeatCushCmd 5;
BA_ "GenSigSendType" SG_ 1210 ICC_FRSeatCushtargetCmd 5;
BA_ "GenSigInvalidValue" SG_ 1210 ICC_FRSeatCushtargetCmd 127;
BA_ "GenSigSendType" SG_ 1210 ICC_FRZeroGravitySeatSw 5;
BA_ "GenSigSendType" SG_ 1210 ICC_HomeLinkArmHornSet 5;
BA_ "GenSigSendType" SG_ 1210 ICC_HomeLinkWelLightSet 5;
BA_ "GenSigSendType" SG_ 1210 ICC_HomeLinkPositionSts 0;
BA_ "GenSigSendType" SG_ 1210 ICC_WelcomeOpenSetCmd 5;
BA_ "GenSigSendType" SG_ 1210 ICC_WALOpenSetCmd 5;
BA_ "GenSigSendType" SG_ 1210 ICC_UIROpenSetCmd 5;
BA_ "GenSigSendType" SG_ 1210 ICC_EnjoyableSeatSwitch 5;
BA_ "GenSigSendType" SG_ 1210 ICC_BLTKeyPESet 5;
BA_ "GenSigSendType" SG_ 1210 ICC_FRMemoryDeleteCmd 5;
BA_ "GenSigSendType" SG_ 1210 ICC_FLSitPosnlocation 5;
BA_ "GenSigSendType" SG_ 1210 ICC_FRSitPosnlocation 5;
BA_ "GenSigSendType" SG_ 1210 ICC_FREasyEntryExitSet 5;
BA_ "GenSigSendType" SG_ 1210 ICC_FRMemoryRecoveryCmd 5;
BA_ "GenSigSendType" SG_ 1210 ICC_ConsoleAdjustSwitch 5;
BA_ "GenSigSendType" SG_ 1399 ICC_SailremainingTime_577h 0;
BA_ "GenSigSendType" SG_ 1399 TotalSailOdoMeterBackUp_577h 0;
BA_ "GenSigSendType" SG_ 1399 SailOdoMeter_577h 0;
BA_ "GenSigSendType" SG_ 1399 MaintenanceOdometer_577h 0;
BA_ "GenSigSendType" SG_ 1399 MaintenanceOdometer_BkpEn_577h 0;
BA_ "GenSigSendType" SG_ 1399 MaintenanceOdometer_Valid_577h 0;
BA_ "GenSigSendType" SG_ 1399 ICC_CLTC_RangeAval 0;
BA_ "GenSigInvalidValue" SG_ 1399 ICC_CLTC_RangeAval 1023;
BA_ "GenSigSendType" SG_ 1399 ICC_DynamicRangeAval 0;
BA_ "GenSigInvalidValue" SG_ 1399 ICC_DynamicRangeAval 1023;
BA_ "GenSigSendType" SG_ 1399 ICC_WLTC_RangeAval 0;
BA_ "GenSigInvalidValue" SG_ 1399 ICC_WLTC_RangeAval 1023;
BA_ "GenSigSendType" SG_ 1399 ICC_CLTC_RangeAvalFuel 0;
BA_ "GenSigInvalidValue" SG_ 1399 ICC_CLTC_RangeAvalFuel 4095;
BA_ "GenSigSendType" SG_ 1399 ICC_WLTC_RangeAvalFuel 0;
BA_ "GenSigInvalidValue" SG_ 1399 ICC_WLTC_RangeAvalFuel 4095;
BA_ "GenSigSendType" SG_ 1399 ICC_DynamicRangeAvalFuel 0;
BA_ "GenSigInvalidValue" SG_ 1399 ICC_DynamicRangeAvalFuel 4095;
BA_ "GenSigSendType" SG_ 1399 ICC_CLTC_RangeAvalComp 0;
BA_ "GenSigInvalidValue" SG_ 1399 ICC_CLTC_RangeAvalComp 4095;
BA_ "GenSigSendType" SG_ 1399 ICC_WLTC_RangeAvalComp 0;
BA_ "GenSigInvalidValue" SG_ 1399 ICC_WLTC_RangeAvalComp 4095;
BA_ "GenSigSendType" SG_ 1399 ICC_DynamicRangeAvalComp 0;
BA_ "GenSigInvalidValue" SG_ 1399 ICC_DynamicRangeAvalComp 4095;
BA_ "GenSigSendType" SG_ 1399 ICC_Conditiontype 0;
BA_ "GenSigSendType" SG_ 1238 ICC_CFSSwitch 5;
BA_ "GenSigSendType" SG_ 1238 ICC_CFSLevelSet 5;
BA_ "GenSigSendType" SG_ 1238 ICC_CFSPosSet 5;
BA_ "GenSigSendType" SG_ 1238 ICC_PM25Switch 5;
BA_ "GenSigSendType" SG_ 1238 ICC_AQSSwitch 5;
BA_ "GenSigSendType" SG_ 1238 ICC_SecSetTemp_C 5;
BA_ "GenSigInvalidValue" SG_ 1238 ICC_SecSetTemp_C 31;
BA_ "GenSigStartValue" SG_ 1238 ICC_SecSetTemp_C 31;
BA_ "GenSigSendType" SG_ 1238 ICC_SecFaceKeySts 5;
BA_ "GenSigSendType" SG_ 1238 ICC_SecFootKeySts 5;
BA_ "GenSigSendType" SG_ 1238 ICC_SecBlowSpeedLevelKeySts 5;
BA_ "GenSigSendType" SG_ 1238 ICC_SecAutoSwitch 5;
BA_ "GenSigSendType" SG_ 1238 ICC_SecCLMSwitch 5;
BA_ "GenSigSendType" SG_ 1238 ICC_ThrSetTemp_C 5;
BA_ "GenSigInvalidValue" SG_ 1238 ICC_ThrSetTemp_C 31;
BA_ "GenSigStartValue" SG_ 1238 ICC_ThrSetTemp_C 31;
BA_ "GenSigSendType" SG_ 1238 ICC_ThrFaceKeySts 5;
BA_ "GenSigSendType" SG_ 1238 ICC_ThrFootKeySts 5;
BA_ "GenSigSendType" SG_ 1238 ICC_ThrBlowSpeedLevelKeySts 5;
BA_ "GenSigSendType" SG_ 1238 ICC_ThrAutoSwitch 5;
BA_ "GenSigSendType" SG_ 1238 ICC_ThrCLMSwitch 5;
BA_ "GenSigSendType" SG_ 1238 ICC_ThrACRequestKeySts 5;
BA_ "GenSigSendType" SG_ 1238 ICC_DFMSwitch 5;
BA_ "GenSigSendType" SG_ 1289 ICC_TirePressureDisplayUnit 0;
BA_ "GenSigSendType" SG_ 1289 ICC_TireTemperatureDisplayUnit 0;
BA_ "GenSigSendType" SG_ 1289 ICC_ToggleUnits 0;
BA_ "GenSigSendType" SG_ 1289 ICC_BtConFlag 0;
BA_ "GenSigSendType" SG_ 1289 ICC_GPSSwitchSet 0;
BA_ "GenSigSendType" SG_ 1167 ICC_WadeModeSet_48Fh 5;
BA_ "GenSigSendType" SG_ 1167 ICC_DeepSnowSet_48Fh 5;
BA_ "GenSigSendType" SG_ 1167 ICC_KeyDriveModememory 5;
BA_ "GenSigSendType" SG_ 1167 ICC_DriveModeSet 5;
BA_ "GenSigSendType" SG_ 1167 ICC_DRIFTModeSetReq 5;
BA_ "GenSigSendType" SG_ 1167 ICC_EXPERTEIPBESPSet 5;
BA_ "GenSigSendType" SG_ 1167 ICC_EXPERTEcoSet 5;
BA_ "GenSigSendType" SG_ 1167 ICC_EXPERTNormSet 5;
BA_ "GenSigSendType" SG_ 1167 ICC_EXPERTSportSet 5;
BA_ "GenSigSendType" SG_ 1167 ICC_CrossaxisSet 5;
BA_ "GenSigSendType" SG_ 1167 ICC_EXPERTRWDSet 5;
BA_ "GenSigSendType" SG_ 1167 ICC_EXPERTAWDSet 5;
BA_ "GenSigSendType" SG_ 1167 ICC_EXPERTAutoSet 5;
BA_ "GenSigSendType" SG_ 1167 ICC_CLIMBSet 5;
BA_ "GenSigSendType" SG_ 1167 ICC_DriveModeExitSet 5;
BA_ "GenSigSendType" SG_ 1167 ICC_Confidencelevel 5;
BA_ "GenSigInvalidValue" SG_ 1167 ICC_Confidencelevel 127;
BA_ "GenSigSendType" SG_ 1167 ICC_V2L_IntlDisChg 5;
BA_ "GenSigSendType" SG_ 1167 ICC_ExhibitionModeSwitch 5;
BA_ "GenSigSendType" SG_ 1167 ICC_TrailerMode 5;
BA_ "GenSigSendType" SG_ 1167 ICC_V2L_DisChgMem 5;
BA_ "GenSigSendType" SG_ 1167 ICC_DrivePowerDispSet 5;
BA_ "GenSigSendType" SG_ 1167 ICC_WLTC_to_CLTC_Mode 5;
BA_ "GenSigSendType" SG_ 1167 ICC_StopChrgnSwitch 5;
BA_ "GenSigSendType" SG_ 1167 ICC_StopChrgnMode 5;
BA_ "GenSigSendType" SG_ 1167 ICC_RegenerateLevelCtrl 5;
BA_ "GenSigSendType" SG_ 1167 ICC_SinglePedalMem 5;
BA_ "GenSigSendType" SG_ 1167 ICC_FuelDetnSwt 5;
BA_ "GenSigSendType" SG_ 1167 ICC_FuelDetnState 5;
BA_ "GenSigSendType" SG_ 1167 ICC_FuelDetnOpDefeated 5;
BA_ "GenSigSendType" SG_ 1167 ICC_HVDownRepairMode 5;
BA_ "GenSigSendType" SG_ 1167 ICC_UTURNSnowSet 5;
BA_ "GenSigSendType" SG_ 1167 ICC_UTURNSandSet 5;
BA_ "GenSigSendType" SG_ 1167 ICC_UTURNMudSet 5;
BA_ "GenSigSendType" SG_ 1167 ICC_UTURNGrassSet 5;
BA_ "GenSigSendType" SG_ 1167 ICC_LTCDispSet2 5;
BA_ "GenSigSendType" SG_ 1167 ICC_SetSocManage 5;
BA_ "GenSigSendType" SG_ 1326 ICC_DWDOnOff_Req 5;
BA_ "GenSigSendType" SG_ 1326 ICC_ContainerLightSet 5;
BA_ "GenSigSendType" SG_ 1331 Set_AMPKeyVolume 5;
BA_ "GenSigSendType" SG_ 1331 ICC_RLSeatEasyEntryExitSet 5;
BA_ "GenSigSendType" SG_ 1331 ICC_RRSeatEasyEntryExitSet 5;
BA_ "GenSigSendType" SG_ 1331 ICC_RLMemoryRecoveryCmd 5;
BA_ "GenSigSendType" SG_ 1331 ICC_RRMemoryRecoveryCmd 5;
BA_ "GenSigSendType" SG_ 1331 ICC_RLSitPosnlocation 5;
BA_ "GenSigSendType" SG_ 1331 ICC_RRSitPosnlocation 5;
BA_ "GenSigSendType" SG_ 1331 ICC_CMSMDisplaySwitch 5;
BA_ "GenSigSendType" SG_ 1331 ICC_CMSMDisplayAdjustmode 5;
BA_ "GenSigSendType" SG_ 1331 ICC_CMSMSetstandardSwitch 5;
BA_ "GenSigSendType" SG_ 1331 ICC_LeftPedalControl 5;
BA_ "GenSigStartValue" SG_ 1331 ICC_LeftPedalControl 3;
BA_ "GenSigSendType" SG_ 1331 ICC_RightPedalControl 5;
BA_ "GenSigStartValue" SG_ 1331 ICC_RightPedalControl 3;
BA_ "GenSigSendType" SG_ 1331 ICC_EPCEnable 5;
BA_ "GenSigSendType" SG_ 1331 ICC_AMPKTVvoiceVolumeSet 5;
BA_ "GenSigSendType" SG_ 1331 ICC_AMPA2BENCSoundReq 5;
BA_ "GenSigSendType" SG_ 1331 ICC_AMPENCVolumeSet 5;
BA_ "GenSigSendType" SG_ 1331 ICC_AMPA2BChimeSoundReq 5;
BA_ "GenSigSendType" SG_ 1331 Set_AMPSoundFocus_2 5;
BA_ "GenSigSendType" SG_ 1331 ICC_AMPA2BKTVvoiceSoundReq 5;
BA_ "GenSigSendType" SG_ 1331 ICC_MedStatusSet 5;
BA_ "GenSigSendType" SG_ 1331 ICC_MedAreaSet 5;
BA_ "GenSigSendType" SG_ 1331 ICC_LeftElectricPedalsSet 5;
BA_ "GenSigSendType" SG_ 1331 ICC_RightElectricPedalsSet 5;
BA_ "GenSigSendType" SG_ 1331 ICC_NapAreaSet2 5;
BA_ "GenSigSendType" SG_ 1331 ICC_DisplayAdjustrAngReq 5;
BA_ "GenSigInvalidValue" SG_ 1331 ICC_DisplayAdjustrAngReq 255;
BA_ "GenSigSendType" SG_ 1331 ICC_CMSMTouchSts 5;
BA_ "GenSigSendType" SG_ 1333 ICC_SRFCmd 5;
BA_ "GenSigSendType" SG_ 1333 ICC_SRFPercentCmd 5;
BA_ "GenSigSendType" SG_ 1333 ICC_CSunshadeReq 5;
BA_ "GenSigSendType" SG_ 1333 ICC_CSunshadePercentReq 5;
BA_ "GenSigSendType" SG_ 1333 ICC_SunshadeCmd 5;
BA_ "GenSigSendType" SG_ 1333 ICC_SunshadePercentCmd 5;
BA_ "GenSigSendType" SG_ 1335 ICC_SandABSCmd_537h 5;
BA_ "GenSigSendType" SG_ 1335 ICC_SandABSSw_537h 5;
BA_ "GenSigSendType" SG_ 1335 ICC_UndergroundModeReq_537h 5;
BA_ "GenSigSendType" SG_ 1335 ICC_InflateReq_537h 5;
BA_ "GenSigSendType" SG_ 1335 ICC_TrekThroughReq_537h 5;
BA_ "GenSigSendType" SG_ 1335 New_Signal_537_3 0;
BA_ "E2EProfile" SG_ 1335 New_Signal_537_3 "*";
BA_ "GenSigSendType" SG_ 1335 New_Signal_537_1 0;
BA_ "E2EProfile" SG_ 1335 New_Signal_537_1 "*";
BA_ "GenSigSendType" SG_ 1335 ICC_RolloverSetCmd 5;
BA_ "GRC_Sig_ASIL" SG_ 1335 ICC_RolloverSetCmd 2;
BA_ "E2EProfile" SG_ 1335 ICC_RolloverSetCmd "*";
BA_ "GenSigSendType" SG_ 1335 ICC_SET_EPS_SteerReturnRmdSts 5;
BA_ "E2EProfile" SG_ 1335 ICC_SET_EPS_SteerReturnRmdSts "*";
BA_ "GenSigSendType" SG_ 1335 ICC_SET_MFSShake 5;
BA_ "E2EProfile" SG_ 1335 ICC_SET_MFSShake "*";
BA_ "GenSigSendType" SG_ 1335 ICC_DMS_1_DistractionLevel 5;
BA_ "E2EProfile" SG_ 1335 ICC_DMS_1_DistractionLevel "*";
BA_ "GenSigSendType" SG_ 1335 ICC_OverLoadWarnShieldSet 5;
BA_ "E2EProfile" SG_ 1335 ICC_OverLoadWarnShieldSet "*";
BA_ "GenSigSendType" SG_ 1335 ICC_BSWReq 5;
BA_ "E2EProfile" SG_ 1335 ICC_BSWReq "*";
BA_ "GenSigSendType" SG_ 1335 ICC_horizontalReq 5;
BA_ "E2EProfile" SG_ 1335 ICC_horizontalReq "*";
BA_ "GenSigSendType" SG_ 1337 ICC_SET_BT_ReduceWindSpeed 5;
BA_ "GenSigSendType" SG_ 1337 ICC_SET_IPM_FirstBlowing 5;
BA_ "GenSigSendType" SG_ 1337 ICC_SET_IPM_BlowerDelay 5;
BA_ "GenSigSendType" SG_ 1337 ICC_SET_CirculationInTunnels 5;
BA_ "GenSigSendType" SG_ 1337 ICC_UVCLuminanceReq 5;
BA_ "GenSigSendType" SG_ 1337 ICC_UVCControlReq 5;
BA_ "GenSigSendType" SG_ 1337 ICC_CrossCountryCoolingReq 5;
BA_ "GenSigSendType" SG_ 1337 ICC_KeepWarmReq 5;
BA_ "GenSigSendType" SG_ 1337 ICC_keepwarmSetTemperatureReq 5;
BA_ "GenSigSendType" SG_ 1337 ICC_ParkingAirConditioning 5;
BA_ "GenSigSendType" SG_ 1337 ICC_CoolantFill_Req 5;
BA_ "GenSigSendType" SG_ 1337 ICC_FraganceLightoffReq 5;
BA_ "GenSigSendType" SG_ 1337 ICC_FraganceMemoffReq 5;
BA_ "GenSigSendType" SG_ 1337 ICC_AirPurgeReminderReq 5;
BA_ "GenSigSendType" SG_ 1337 ICC_BiochemicalFuncReq 5;
BA_ "GenSigSendType" SG_ 1337 ICC_TimedVentilationReq 5;
BA_ "GenSigSendType" SG_ 1337 ICC_PetmodeSetTemperature_L_C 5;
BA_ "GenSigInvalidValue" SG_ 1337 ICC_PetmodeSetTemperature_L_C 31;
BA_ "GenSigStartValue" SG_ 1337 ICC_PetmodeSetTemperature_L_C 31;
BA_ "GenSigSendType" SG_ 1337 ICC_PetModeSetTemperature_R_C 5;
BA_ "GenSigInvalidValue" SG_ 1337 ICC_PetModeSetTemperature_R_C 31;
BA_ "GenSigStartValue" SG_ 1337 ICC_PetModeSetTemperature_R_C 31;
BA_ "GenSigSendType" SG_ 1337 ICC_PetModeSetCLMOn 5;
BA_ "GenSigSendType" SG_ 1337 ICC_PetModeSetAutoKeySts 5;
BA_ "GenSigSendType" SG_ 1337 ICC_PetModeSetCirculationSts 5;
BA_ "GenSigSendType" SG_ 1318 ICC_SET_TDL_Rhythm_Switch 5;
BA_ "GenSigSendType" SG_ 1318 ICC_SET_TDL_Switch 5;
BA_ "GenSigSendType" SG_ 1318 ICC_SET_TDL_ColourModeAdj 5;
BA_ "GenSigSendType" SG_ 1318 ICC_VoiceWake 5;
BA_ "GenSigSendType" SG_ 1318 ICC_TDL_RhythmReq 5;
BA_ "GenSigSendType" SG_ 1318 ICC_SET_ApiluminanceAdj 5;
BA_ "GenSigSendType" SG_ 1318 ICC_SET_MusicLoudness_120HZ 0;
BA_ "GenSigSendType" SG_ 1318 ICC_SET_MusicLoudness_250HZ 0;
BA_ "GenSigSendType" SG_ 1318 ICC_SET_MusicLoudness_500HZ 0;
BA_ "GenSigSendType" SG_ 1318 ICC_SET_MusicLoudness_1000HZ 0;
BA_ "GenSigSendType" SG_ 1318 ICC_SET_MusicLoudness_1500HZ 0;
BA_ "GenSigSendType" SG_ 1318 ICC_SET_MusicLoudness_2000HZ 0;
BA_ "GenSigSendType" SG_ 1318 ICC_SET_MusicLoudness_6000HZ 0;
BA_ "GenSigSendType" SG_ 1318 ICC_TDL_FlowLightSw 5;
BA_ "GenSigSendType" SG_ 1318 ICC_TDL_FlowLightModeAdj 5;
BA_ "GenSigSendType" SG_ 1318 ICC_SET_256ColourAdj 5;
BA_ "GenSigInvalidValue" SG_ 1318 ICC_SET_256ColourAdj 127;
BA_ "GenSigStartValue" SG_ 1318 ICC_SET_256ColourAdj 127;
BA_ "GenSigSendType" SG_ 1320 ICC_Chb_Req 5;
BA_ "GenSigSendType" SG_ 1320 ICC_ChbMem_Req 5;
BA_ "GenSigSendType" SG_ 1320 ICC_ChbDelay_Req 5;
BA_ "GenSigSendType" SG_ 1320 ICC_ChbSterilization_Req 5;
BA_ "GenSigSendType" SG_ 1320 ICC_ChbItemsLeft_Req 5;
BA_ "GenSigSendType" SG_ 1320 ICC_ParkingRadarSwSet 5;
BA_ "GenSigSendType" SG_ 1320 ICC_ChbTimeset_Req 5;
BA_ "GenSigInvalidValue" SG_ 1320 ICC_ChbTimeset_Req 31;
BA_ "GenSigSendType" SG_ 1320 ICC_ChbCoolset_Req 5;
BA_ "GenSigSendType" SG_ 1320 ICC_ChbCoolorheat_Req 5;
BA_ "GenSigSendType" SG_ 1320 ICC_ChbHeatset_Req 5;
BA_ "GenSigSendType" SG_ 1360 ICC_LISD_DisplaySwitch 5;
BA_ "GenSigSendType" SG_ 1360 ICC_LISD_ParkingShowCMD 5;
BA_ "GenSigSendType" SG_ 1360 ICC_RoofCampLampSetL 5;
BA_ "GenSigSendType" SG_ 1360 ICC_RISD_DisplaySwitch 5;
BA_ "GenSigSendType" SG_ 1360 ICC_RISD_ParkingShowCMD 5;
BA_ "GenSigSendType" SG_ 1360 ICC_RoofCampLampSetR 5;
BA_ "GenSigSendType" SG_ 1360 ICC_LogoParkingReq 5;
BA_ "GenSigSendType" SG_ 1360 ICC_LogoChargingReq 5;
BA_ "GenSigSendType" SG_ 1360 ICC_DRLSw 5;
BA_ "GenSigSendType" SG_ 1360 ICC_TopLightSet 5;
BA_ "GenSigSendType" SG_ 1360 ICC_APillarYellowAmbientSet 5;
BA_ "GenSigSendType" SG_ 1360 ICC_APillarWhiteAmbientSet 5;
BA_ "GenSigSendType" SG_ 1360 ICC_LISD_ParkingShowMod 5;
BA_ "GenSigSendType" SG_ 1360 ICC_RISD_ParkingShowMod 5;
BA_ "GenSigSendType" SG_ 1360 ICC_APillarSpotLampSet 5;
BA_ "GenSigSendType" SG_ 1360 ICC_PenetrationLampSetF 5;
BA_ "GenSigSendType" SG_ 1360 ICC_MusicLampShowSW 5;
BA_ "GenSigSendType" SG_ 1360 ICC_LogoColorReq 5;
BA_ "GenSigSendType" SG_ 1360 ICC_XDriveMode 0;
VAL_ 1265 ICC_PwrOff 0 "No active" 1 "Active" ;
VAL_ 1265 ICC_EtmEgySave 0 "OFF" 1 "ON" ;
VAL_ 1265 ICC_HoodSW 0 "Not Active" 1 "ON" 2 "Reserved" 3 "Reserved" ;
VAL_ 1265 ICC_GloveboxSW 0 "Not Active" 1 "ON" 2 "Reserved" 3 "Reserved" ;
VAL_ 1265 ICC_ChrgPortCover_Switch 0 "Not Active" 1 "ON" 2 "OFF" 3 "Reserved" ;
VAL_ 1265 ICC_ReWinDefrstSwt 0 "Not Active" 1 "ON" 2 "OFF" 3 "Reserved" ;
VAL_ 1265 ICC_RearMirrorFoldCmd 0 "Not Active" 1 "Fold" 2 "Unfold" 3 "Reserved" ;
VAL_ 1265 ICC_CenterLockSwt 0 "Not Active" 1 "UNLOCK" 2 "LOCK" 3 "Reserved" ;
VAL_ 1265 ICC_ReverseExtMirrorSts 0 "Not active" 1 "OFF" 2 "Only right side" 3 "Only left side" 4 "Both sides" 5 "Not Used" 6 "Not Used" 7 "Not Used" ;
VAL_ 1265 ICC_LightMainSwitchSts 0 "Not active" 1 "Off" 2 "Auto" 3 "PositionLampSwitch" 4 "LowBeamSwitch" 5 "Reserved" 6 "Reserved" 7 "Reserved" ;
VAL_ 1265 ICC_AutoFoldSts 0 "Not active" 1 "Autofold mode" 2 "Not autofold mode" 3 "Not used" ;
VAL_ 1265 ICC_HeadlampHeightSts 0 "Not active" 1 "Level 0" 2 "Level 1" 3 "Level 2" 4 "Level 3" 5 "Not Used" 6 "Not Used" 7 "Not Used" ;
VAL_ 1265 ICC_WiprSnvty 0 "Not Active" 1 "Level1" 2 "Level2" 3 "Level3" 4 "Level4" 5 "Reserved" 6 "Reserved" ;
VAL_ 1265 ICC_WindowCmd 0 "Not active" 1 "FLWindow open" 2 "FLWindow close" 3 "FRWindow open" 4 "FRWindow close" 5 "RLWindow open" 6 "RLWindow close" 7 "RRWindow open" 8 "RRWindow close" 9 "Front Windows open" 10 "Front Windows close" 11 "Rear Windows open" 12 "Rear Windows close" 13 "All Windows open" 14 "All  Windows close" 15 "All  Windows comfort" 16 "Not used" 17 "Not used" 18 "Not used" 19 "Not used" 20 "Not used" 21 "Not used" 22 "Not used" 23 "Not used" 24 "Not used" 25 "Not used" 26 "Not used" 27 "Not used" 28 "Not used" 29 "Not used" 30 "Not used" 31 "Not used" ;
VAL_ 1265 ICC_LowBeamDelayOff 0 "Not Active" 1 "0s" 2 "10s" 3 "20s" 4 "30s" 5 "60s" 6 "Not Used" 7 "Not Used" ;
VAL_ 1265 ICC_FGHeatSts 0 "Not Active" 1 "ON" 2 "OFF" 3 "Reserved" ;
VAL_ 1265 ICC_AutolockSts 0 "Not active" 1 "Autolock mode" 2 "Not autolock mode" 3 "Not Used" ;
VAL_ 1265 ICC_WiperID 0 "Not Active" 1 "Front Wiper" 2 "Rear Wiper" 3 "Both Wiper" ;
VAL_ 1265 ICC_MaintenanceMode 0 "Not Active" 1 "Exit" 2 "Entrance" 3 "Reserved" ;
VAL_ 1265 ICC_lockSetSwitchSts 0 "Not Active" 1 "OFF" 2 "Only Lighting" 3 "Sound and Lighting" ;
VAL_ 1265 ICC_ChildLockSW 0 "Not Active" 1 "Window" 2 "ChildLock_RL" 3 "ChildLock_RR" ;
VAL_ 1265 ICC_ParkUnlockEnable 0 "Not Active" 1 "Disable" 2 "Enable" 3 "Reserved" ;
VAL_ 1265 ICC_BLEOpenDriverDoorEnable 0 "No Request" 1 "Enable" 2 "Disable" 3 "Reserved" ;
VAL_ 1265 ICC_WinInhbSwt 0 "Not Active" 1 "Inhibit" 2 "Permit" 3 "Reserved" ;
VAL_ 1265 ICC_SteerWhlHeatgSwt 0 "Not Active" 1 "Level1" 2 "Level2" 3 "Level3" 4 "OFF" ;
VAL_ 1265 ICC_AutoHeatingset 0 "Not Active" 1 "ON" 2 "OFF" 3 "Reserved" ;
VAL_ 1265 ICC_FrontFogSw 0 "Not Active" 1 "ON" 2 "OFF" 3 "Reserved" ;
VAL_ 1265 ICC_RearFogSw 0 "Not Active" 1 "ON" 2 "OFF" 3 "Reserved" ;
VAL_ 1265 ICC_DoorControlSW 0 "Not Active" 1 "ON" 2 "OFF" 3 "Reserved" ;
VAL_ 1265 ICC_LockCarWinCloseSw 0 "Not Active" 1 "ON" 2 "OFF" 3 "Reserved" ;
VAL_ 1265 ICC_RainCarWinCloseSw 0 "Not Active" 1 "ON" 2 "OFF" 3 "Reserved" ;
VAL_ 1265 ICC_EasyEntryExitSet 0 "Not Active" 1 "ON" 2 "OFF" 3 "Not Used" ;
VAL_ 1265 ICC_NapTimeSet 0 "Not Active" ;
VAL_ 1265 ICC_NapAreaSet 0 "Not Active" 1 "Front Left" 2 "Front Right" 3 "Front Left and Right" ;
VAL_ 1265 ICC_NapStatusSet 0 "Not Active" 1 "ON" 2 "OFF" 3 "Not Used" ;
VAL_ 1265 ICC_NapCFSStatusSet 0 "Not Active" 1 "On" 2 "Off" 3 "Not Used" ;
VAL_ 1265 ICC_NapSetTemperature 31 "Not active" ;
VAL_ 1265 ICC_SpoilerWelcomeFunSet 0 "Not Active" 1 "ON" 2 "OFF" 3 "Reserved" ;
VAL_ 1265 ICC_SpoilerCtrlCmd 0 "Not Active" 1 "Auto" 2 "Open Level1" 3 "Open Level2" 4 "Close" 5 "Reserved" 6 "Reserved" 7 "Reserved" ;
VAL_ 1265 ICC_HazardLightReq 0 "Not Active" 1 "ON" 2 "OFF" 3 "Not Used" ;
VAL_ 1265 ICC_MusicStatus 0 "Not Active" 1 "ON" 2 "OFF" 3 "Not Used" ;
VAL_ 1265 ICC_CinemaStatus 0 "Not Active" 1 "ON" 2 "OFF" 3 "Not Used" ;
VAL_ 1137 ICC_BookChrgSetReq 0 "default" 1 "BookSet" 2 "CancellBook" 3 "Reserved" ;
VAL_ 1137 ICC_BkChrgCycleType 0 "default" 1 "Once" 2 "EveryDay" 3 "WorkDay" 4 "Reserved" 5 "Reserved" ;
VAL_ 1137 ICC_StopChrgReq 0 "Not Active" 1 "Active" ;
VAL_ 1137 ICC_BkChrgCycleMon 0 "Not active" 1 "Active" ;
VAL_ 1137 ICC_BkChrgCycleTues 0 "Not active" 1 "Active" ;
VAL_ 1137 ICC_BkChrgCycleWen 0 "Not active" 1 "Active" ;
VAL_ 1137 ICC_BkChrgCycleThur 0 "Not active" 1 "Active" ;
VAL_ 1137 ICC_BkChrgCycleFri 0 "Not active" 1 "Active" ;
VAL_ 1137 ICC_BkChrgCycleSat 0 "Not active" 1 "Active" ;
VAL_ 1137 ICC_BkChrgCycleSun 0 "Not active" 1 "Active" ;
VAL_ 1137 ICC_PetmodeFb 0 "Not active" 1 "ON" 2 "OFF" 3 "Invalid" ;
VAL_ 1137 ICC_SentinelModeSwitchSts 0 "Not active" 1 "ON" 2 "OFF" 3 "Reserved" ;
VAL_ 1137 ICC_SentinelModeWorkingSts 0 "Not Active" 1 "Active" 2 "LowSOC" 3 "HVNotReady" 4 "HVFault" 5 "MirrorUnFold" 6 "CameraFault" 7 "LowBatVolt" ;
VAL_ 1137 ICC_SentinelModeFaultSts 0 "Not Warming" 1 "Artificial occlusion" 2 "Rain and snow cover" 3 "Reserved" ;
VAL_ 1137 ICC_SentinelModeAlarmSts 0 "Not Alarm" 1 "Level 1" 2 "Level 2" 3 "Level 3" ;
VAL_ 1137 ICC_SentinelModeExitReason 0 "Normal" 1 "LowSOC" 2 "HVNotReady" 3 "HVFault" 4 "MirrorUnFold" 5 "CameraFault" 6 "LowBatVolt" ;
VAL_ 1137 ICC_PetModeWarn 0 "Not Active" 1 "High Voltage Battery Low" 2 "TMS Abnormal" 3 "High Pressure Abnormal" 4 "Low Voltage Battery Low" 5 "High Voltage Battery Less Than 15%" 6 "High Voltage Battery Less Than 12%" 7 "Time Long Warning" ;
VAL_ 1137 ICC_TBOXPetmodeReq 0 "Not Active" 1 "ON" 2 "OFF" 3 "Reserved" ;
VAL_ 1137 ICC_PetModeWarn_2 0 "Not Active" 1 "High Voltage Battery Low" 2 "TMS Abnormal" 3 "High Pressure Abnormal" 4 "Low Voltage Battery Low" 5 "High Voltage Battery Less Than 15%" 6 "High Voltage Battery Less Than 12%" 7 "Time Long Warning" 8 "Vehicle charging" 9 "Vehicle Disarming" 10 "Gear is non-p" ;
VAL_ 1137 ICM_FuelLevelFailSts 0 "Fail_Not_Present" 1 "Fail_Present" ;
VAL_ 1137 ICM_Maintenance_tips 0 "Tip_Not_Present" 1 "Tip_Present" ;
VAL_ 1144 ICC_HvBattKeepWarmSet 0 "Not active" 1 "active" ;
VAL_ 1144 ICC_EnergyRegSet 0 "Not active" ;
VAL_ 1144 ICC_HvBattKeepWarmActiveReq 0 "Not active" 1 "StartWarm" 2 "EndWarm" 3 "Not Used" ;
VAL_ 1210 ICC_FLSeatHeiCmd 0 "Not active" 1 "Move Forwardwarde" 2 "Move Bacwardkwarde" 3 "Reserved" ;
VAL_ 1210 ICC_FLSeatLvlCmd 0 "Not active" 1 "Move Forwardwarde" 2 "Move Bacwardkwarde" 3 "Reserved" ;
VAL_ 1210 ICC_FLSeatBackAgCmd 0 "Not active" 1 "Move Forwardwarde" 2 "Move Bacwardkwarde" 3 "Reserved" ;
VAL_ 1210 ICC_FLSeatCushCmd 0 "Not active" 1 "Move Forwardwarde" 2 "Move Bacwardkwarde" 3 "Reserved" ;
VAL_ 1210 ICC_FLSeatLegSpprtCmd 0 "Not active" 1 "Move Forwardwarde" 2 "Move Bacwardkwarde" 3 "Reserved" ;
VAL_ 1210 ICC_FRSeatHeiCmd 0 "Not active" 1 "Move Forwardwarde" 2 "Move Bacwardkwarde" 3 "Reserved" ;
VAL_ 1210 ICC_FRSeatLvlCmd 0 "Not active" 1 "Move Forwardwarde" 2 "Move Bacwardkwarde" 3 "Reserved" ;
VAL_ 1210 ICC_FRSeatBackAgCmd 0 "Not active" 1 "Move Forwardwarde" 2 "Move Bacwardkwarde" 3 "Reserved" ;
VAL_ 1210 ICC_FRSeatLegSpprtCmd 0 "Not active" 1 "Move Forwardwarde" 2 "Move Bacwardkwarde" 3 "Reserved" ;
VAL_ 1210 ICC_MemoryRecoveryCmd 0 "Not Active" 1 "Save" 2 "Recover Manual" 3 "RecoverAuto" ;
VAL_ 1210 ICC_DeleteFaceID 0 "Not active" 1 "ID1" 2 "ID2" 3 "ID3" 4 "ID4" 5 "ID5" 6 "Not Used" 7 "Not Used" ;
VAL_ 1210 ICC_FLSeatHeitargetCmd 0 "Not active" ;
VAL_ 1210 ICC_FLSeatLvltargetCmd 0 "Not active" ;
VAL_ 1210 ICC_FLSeatBackAgtargetCmd 0 "Not active" ;
VAL_ 1210 ICC_FLSeatCushtargetCmd 0 "Not active" ;
VAL_ 1210 ICC_FLSeatLegSpprttargetCmd 0 "Not active" ;
VAL_ 1210 ICC_FRSeatHeitargetCmd 0 "Not active" ;
VAL_ 1210 ICC_FRSeatLvltargetCmd 0 "Not active" ;
VAL_ 1210 ICC_FRSeatBackAgtargetCmd 0 "Not active" ;
VAL_ 1210 ICC_FRSeatLegSpprttargetCmd 0 "Not active" ;
VAL_ 1210 ICC_NapFLSeatBackAgtargetSet 0 "Not active" ;
VAL_ 1210 ICC_NapFRSeatBackAgtargetSet 0 "Not active" ;
VAL_ 1210 ICC_NapFLSeatLvltargetSet 0 "Not active" ;
VAL_ 1210 ICC_NapFRSeatLvltargetSet 0 "Not active" ;
VAL_ 1210 ICC_FRSeatLegRestAngleCmd 0 "Not Active" 1 "Move Forwardwarde" 2 "Move Bacwardkwarde" 3 "Reserved" ;
VAL_ 1210 ICC_FRSeatLegRestAngletargetCmd 0 "Not active" ;
VAL_ 1210 ICC_FRSeatCushCmd 0 "Not Active" 1 "Move Forwardwarde" 2 "Move Bacwardkwarde" 3 "Reserved" ;
VAL_ 1210 ICC_FRSeatCushtargetCmd 0 "Not Active" ;
VAL_ 1210 ICC_FRZeroGravitySeatSw 0 "Not Active" 1 "OFF" 2 "ON" 3 "Reserved" ;
VAL_ 1210 ICC_HomeLinkArmHornSet 0 "Not Active" 1 "ON" 2 "OFF" 3 "Not Used" ;
VAL_ 1210 ICC_HomeLinkWelLightSet 0 "Not Active" 1 "ON" 2 "OFF" 3 "Not Used" ;
VAL_ 1210 ICC_HomeLinkPositionSts 0 "Not Active" 1 "At home" 2 "Not at home" 3 "Reserved" ;
VAL_ 1210 ICC_WelcomeOpenSetCmd 0 "Not Active" 1 "ON" 2 "OFF" 3 "Not Used" ;
VAL_ 1210 ICC_WALOpenSetCmd 0 "Not Active" 1 "ON" 2 "OFF" 3 "Not Used" ;
VAL_ 1210 ICC_UIROpenSetCmd 0 "Not Active" 1 "ON" 2 "OFF" 3 "Not Used" ;
VAL_ 1210 ICC_EnjoyableSeatSwitch 0 "Not Active" 1 "Entrence" 2 "Exit" 3 "Pause" ;
VAL_ 1210 ICC_BLTKeyPESet 0 "Not Active" 1 "ON" 2 "OFF" 3 "Not Used" ;
VAL_ 1210 ICC_FRMemoryDeleteCmd 0 "Not Active" 1 "Delete" 2 "Not Used" 3 "Not Used" ;
VAL_ 1210 ICC_FLSitPosnlocation 0 "Not Active" 1 "Location1" 2 "Location2" 3 "Location3" ;
VAL_ 1210 ICC_FRSitPosnlocation 0 "Not Active" 1 "Location1" 2 "Location2" 3 "Location3" ;
VAL_ 1210 ICC_FREasyEntryExitSet 0 "Not Active" 1 "ON" 2 "OFF" 3 "Not Used" ;
VAL_ 1210 ICC_FRMemoryRecoveryCmd 0 "Not Active" 1 "Save" 2 "Recover Manual" 3 "RecoverAuto" ;
VAL_ 1210 ICC_ConsoleAdjustSwitch 0 "Not Active" 1 "Lock" 2 "Unlock" 3 "Forward(Reserved)" 4 "Backward(Reserved)" 5 "Delpoy" 6 "Retract" 7 "Middle" 8 "Stop" ;
VAL_ 1399 ICC_Conditiontype 0 "Default" 1 "Dynamics" 2 "CLTC" 3 "WLTC" ;
VAL_ 1238 ICC_CFSSwitch 0 "Not Active" 1 "ON" 2 "OFF" 3 "Not Used" ;
VAL_ 1238 ICC_CFSLevelSet 0 "Not Active" 1 "Level 1" 2 "Level 2" 3 "Level 3" 4 "Reserved" 5 "Reserved" 6 "Reserved" 7 "Reserved" ;
VAL_ 1238 ICC_CFSPosSet 0 "Not Active" 1 "Position One" 2 "Position Two" 3 "Position Three" ;
VAL_ 1238 ICC_PM25Switch 0 "Not Active" 1 "ON" 2 "OFF" 3 "Not Used" ;
VAL_ 1238 ICC_AQSSwitch 0 "Not Active" 1 "ON" 2 "OFF" 3 "Not Used" ;
VAL_ 1238 ICC_SecSetTemp_C 31 "Not Active" ;
VAL_ 1238 ICC_SecFaceKeySts 0 "Not Active" 1 "ON" 2 "OFF" 3 "Not Used" ;
VAL_ 1238 ICC_SecFootKeySts 0 "Not Active" 1 "ON" 2 "OFF" 3 "Not Used" ;
VAL_ 1238 ICC_SecBlowSpeedLevelKeySts 0 "Not Active" 1 "Level  1" 2 "Level  2" 3 "Level  3" 4 "Level  4" 5 "Level  5" 6 "Level  6" 7 "Level  7" 8 "Reserved" 9 "Reserved" 10 "Reserved" 11 "Reserved" 12 "Reserved" 13 "Reserved" 14 "Reserved" 15 "Reserved" ;
VAL_ 1238 ICC_SecAutoSwitch 0 "Not Active" 1 "ON" 2 "OFF" 3 "Not Used" ;
VAL_ 1238 ICC_SecCLMSwitch 0 "Not Active" 1 "ON" 2 "OFF" 3 "Not Used" ;
VAL_ 1238 ICC_ThrSetTemp_C 31 "Not Active" ;
VAL_ 1238 ICC_ThrFaceKeySts 0 "Not Active" 1 "ON" 2 "OFF" 3 "Not Used" ;
VAL_ 1238 ICC_ThrFootKeySts 0 "Not Active" 1 "ON" 2 "OFF" 3 "Not Used" ;
VAL_ 1238 ICC_ThrBlowSpeedLevelKeySts 0 "Not Active" 1 "Level  1" 2 "Level  2" 3 "Level  3" 4 "Level  4" 5 "Level  5" 6 "Level  6" 7 "Level  7" 8 "Level  0" 9 "Reserved" 10 "Reserved" 11 "Reserved" 12 "Reserved" 13 "Reserved" 14 "Reserved" 15 "Reserved" ;
VAL_ 1238 ICC_ThrAutoSwitch 0 "Not Active" 1 "ON" 2 "OFF" 3 "Not Used" ;
VAL_ 1238 ICC_ThrCLMSwitch 0 "Not Active" 1 "ON" 2 "OFF" 3 "Not Used" ;
VAL_ 1238 ICC_ThrACRequestKeySts 0 "Not Active" 1 "ON" 2 "OFF" 3 "Not used" ;
VAL_ 1238 ICC_DFMSwitch 0 "Not Active" 1 "ON" 2 "OFF" 3 "Not Used" ;
VAL_ 1289 ICC_TirePressureDisplayUnit 0 "Not Active" 1 "kPa" 2 "bar" 3 "psi" ;
VAL_ 1289 ICC_TireTemperatureDisplayUnit 0 "Not Active" 1 "°C" 2 "F" 3 "Reserved" ;
VAL_ 1289 ICC_ToggleUnits 0 "Not Active" 1 "Imperial" 2 "Metric" 3 "Reserved" ;
VAL_ 1289 ICC_BtConFlag 0 "invalid" 1 "bluetooth not found" 2 "PIN error" 3 "other anomalies" 4 "bluetooth connection successful" ;
VAL_ 1289 ICC_GPSSwitchSet 0 "Not Active" 1 "On" 2 "Off" 3 "Not Used" ;
VAL_ 1167 ICC_KeyDriveModememory 0 "Not Active" 1 "ON" 2 "OFF" 3 "Reserved" ;
VAL_ 1167 ICC_DriveModeSet 0 "Not Active" 1 "ECO" 2 "NORMAL" 3 "SPORT" 4 "SNOW" 5 "MUD" 6 "OffRoad" 7 "SAND" 8 "ROCK" 9 "EXPERT" 10 "X" 11 "WADE" 12 "UTURN" 13 "DRIFT" 14 "TOW" 15 "OffroadRace" 16 "Reserved" 17 "Reserved" 18 "Reserved" 19 "Reserved" 20 "Reserved" 21 "Reserved" 22 "Reserved" 23 "Reserved" 24 "Reserved" 25 "Reserved" 26 "Reserved" 27 "Reserved" 28 "Reserved" 29 "Reserved" 30 "Reserved" 31 "Reserved" ;
VAL_ 1167 ICC_DRIFTModeSetReq 0 "Not active" 1 "Entry Mode" 2 "Master mode" 3 "Expert mode" ;
VAL_ 1167 ICC_EXPERTEIPBESPSet 0 "Not Active" 1 "TCS_VDC_OFF" 2 "ALL_ON" 3 "ALL_OFF" ;
VAL_ 1167 ICC_EXPERTEcoSet 0 "Not Active" 1 "ON" 2 "OFF" 3 "Reserved" ;
VAL_ 1167 ICC_EXPERTNormSet 0 "NotActive" 1 "ON" 2 "OFF" 3 "Reserved" ;
VAL_ 1167 ICC_EXPERTSportSet 0 "Not Active" 1 "ON" 2 "OFF" 3 "Reserved" ;
VAL_ 1167 ICC_CrossaxisSet 0 "Not Active" 1 "ON" 2 "OFF" 3 "Reserved" ;
VAL_ 1167 ICC_EXPERTRWDSet 0 "Not Active" 1 "ON" 2 "OFF" 3 "Reserved" ;
VAL_ 1167 ICC_EXPERTAWDSet 0 "Not Active" 1 "ON" 2 "OFF" 3 "Reserved" ;
VAL_ 1167 ICC_EXPERTAutoSet 0 "Not Active" 1 "ON" 2 "OFF" 3 "Reserved" ;
VAL_ 1167 ICC_CLIMBSet 0 "Not Active" 1 "ON" 2 "OFF" 3 "Reserved" ;
VAL_ 1167 ICC_DriveModeExitSet 0 "Not Active" 1 "ON" 2 "OFF" 3 "Reserved" ;
VAL_ 1167 ICC_V2L_IntlDisChg 0 "Not Active" 1 "OFF" 2 "IntelV2L ON" 3 "Reserved" ;
VAL_ 1167 ICC_ExhibitionModeSwitch 0 "Not Active" 1 "ON" 2 "OFF" 3 "Reserved" ;
VAL_ 1167 ICC_TrailerMode 0 "Not Active" 1 "ON" 2 "OFF" 3 "Reserved" ;
VAL_ 1167 ICC_V2L_DisChgMem 0 "Not Active" 1 "Remember" 2 "No Remember" 3 "Reserved" ;
VAL_ 1167 ICC_DrivePowerDispSet 0 "Not Active" 1 "PercentDisp" 2 "kWDisp" 3 "Reserved" ;
VAL_ 1167 ICC_WLTC_to_CLTC_Mode 0 "Not Active" 1 "CLTC" 2 "WLTC" 3 "Reserved" ;
VAL_ 1167 ICC_StopChrgnSwitch 0 "Not Active" 1 "ON" 2 "OFF" 3 "Reserved" ;
VAL_ 1167 ICC_StopChrgnMode 0 "Not Active" 1 "Silence" 2 "Quick" 3 "Reserved" ;
VAL_ 1167 ICC_RegenerateLevelCtrl 0 "Not Active" 1 "Low" 2 "High" 3 "middle" 4 "SinglePedl" 5 "Reserved" 6 "Reserved" 7 "Reserved" ;
VAL_ 1167 ICC_SinglePedalMem 0 "Not Active" 1 "ON" 2 "OFF" 3 "Reserved" ;
VAL_ 1167 ICC_FuelDetnSwt 0 "Not Active" 1 "ON" 2 "OFF" 3 "Reserved" ;
VAL_ 1167 ICC_FuelDetnState 0 "Not Active" 1 "High Idle" 2 "Low Idle" 3 "Reserved" ;
VAL_ 1167 ICC_FuelDetnOpDefeated 0 "No Prompt" 1 "Prompt" ;
VAL_ 1167 ICC_HVDownRepairMode 0 "Not Active" 1 "ON" 2 "OFF" 3 "Reserved" ;
VAL_ 1167 ICC_UTURNSnowSet 0 "Not Active" 1 "ON" 2 "OFF" 3 "Reserved" ;
VAL_ 1167 ICC_UTURNSandSet 0 "Not Active" 1 "ON" 2 "OFF" 3 "Reserved" ;
VAL_ 1167 ICC_UTURNMudSet 0 "Not Active" 1 "ON" 2 "OFF" 3 "Reserved" ;
VAL_ 1167 ICC_UTURNGrassSet 0 "Not Active" 1 "ON" 2 "OFF" 3 "Reserved" ;
VAL_ 1167 ICC_LTCDispSet2 0 "Not Active" 1 "WLTC" 2 "CLTC" 3 "Reserved" ;
VAL_ 1167 ICC_SetSocManage 0 "NotActive" 1 "Default" 2 "SAVE" 3 "Auto" 4 "Charge" 5 "Reserved" 6 "Reserved" 7 "Reserved" ;
VAL_ 1326 ICC_DWDOnOff_Req 0 "Not Active" 1 "ON" 2 "OFF" 3 "Reserved" ;
VAL_ 1326 ICC_ContainerLightSet 0 "Not_Active" 1 "ON" 2 "OFF" 3 "reserved" ;
VAL_ 1331 ICC_RLSeatEasyEntryExitSet 0 "Not Active" 1 "ON" 2 "OFF" 3 "Not Used" ;
VAL_ 1331 ICC_RRSeatEasyEntryExitSet 0 "Not Active" 1 "ON" 2 "OFF" 3 "Not Used" ;
VAL_ 1331 ICC_RLMemoryRecoveryCmd 0 "Not Active" 1 "Save" 2 "Recover Manual" 3 "RecoverAuto" ;
VAL_ 1331 ICC_RRMemoryRecoveryCmd 0 "Not Active" 1 "Save" 2 "Recover Manual" 3 "RecoverAuto" ;
VAL_ 1331 ICC_RLSitPosnlocation 0 "Not Active" 1 "Location1" 2 "Location2" 3 "Location3" ;
VAL_ 1331 ICC_RRSitPosnlocation 0 "Not Active" 1 "Location1" 2 "Location2" 3 "Location3" ;
VAL_ 1331 ICC_CMSMDisplaySwitch 0 "Not active" 1 "ON" 2 "OFF" 3 "Reserved" ;
VAL_ 1331 ICC_CMSMDisplayAdjustmode 0 "Not active" 1 "NormalAngle" 2 "ViewAngle" 3 "Reserved" ;
VAL_ 1331 ICC_CMSMSetstandardSwitch 0 "Not active" 1 "ON" 2 "OFF" 3 "Reserved" ;
VAL_ 1331 ICC_LeftPedalControl 0 "Not active" 1 "Spread_LeftPedal" 2 "Retract_LeftPedal" 3 "Auto" ;
VAL_ 1331 ICC_RightPedalControl 0 "Not active" 1 "Spread_RightPedal" 2 "Retract_RightPedal" 3 "Auto" ;
VAL_ 1331 ICC_EPCEnable 0 "Not active" 1 "ON" 2 "OFF" 3 "Reserved" ;
VAL_ 1331 ICC_AMPKTVvoiceVolumeSet 0 "Not Active" 1 "0" 2 "1" 3 "2" 4 "3" 5 "4" 6 "5" 7 "6" 8 "7" 9 "8" 10 "9" 11 "10" 12 "11" 13 "12" 14 "13" 15 "14" 16 "15" 17 "16" 18 "17" 19 "18" 20 "19" 21 "20" 22 "21" 23 "22" 24 "23" 25 "24" 26 "25" 27 "26" 28 "27" 29 "28" 30 "29" 31 "30" 32 "31" 33 "Reserved" 34 "Reserved" 35 "Reserved" 36 "Reserved" 37 "Reserved" 38 "Reserved" 39 "Reserved" 40 "Reserved" 41 "Reserved" 42 "Reserved" 43 "Reserved" 44 "Reserved" 45 "Reserved" 46 "Reserved" 47 "Reserved" 48 "Reserved" 49 "Reserved" 50 "Reserved" 51 "Reserved" 52 "Reserved" 53 "Reserved" 54 "Reserved" 55 "Reserved" 56 "Reserved" 57 "Reserved" 58 "Reserved" 59 "Reserved" 60 "Reserved" 61 "Reserved" 62 "Reserved" 63 "Reserved" ;
VAL_ 1331 ICC_AMPA2BENCSoundReq 0 "Not Active" 1 "ON" 2 "OFF" 3 "Reserved" ;
VAL_ 1331 ICC_AMPENCVolumeSet 0 "Not Active" 1 "0" 2 "1" 3 "2" 4 "3" 5 "4" 6 "5" 7 "6" 8 "7" 9 "8" 10 "9" 11 "10" 12 "11" 13 "12" 14 "13" 15 "14" 16 "15" 17 "16" 18 "17" 19 "18" 20 "19" 21 "20" 22 "21" 23 "22" 24 "23" 25 "24" 26 "25" 27 "26" 28 "27" 29 "28" 30 "29" 31 "30" 32 "31" 33 "Reserved" 34 "Reserved" 35 "Reserved" 36 "Reserved" 37 "Reserved" 38 "Reserved" 39 "Reserved" 40 "Reserved" 41 "Reserved" 42 "Reserved" 43 "Reserved" 44 "Reserved" 45 "Reserved" 46 "Reserved" 47 "Reserved" 48 "Reserved" 49 "Reserved" 50 "Reserved" 51 "Reserved" 52 "Reserved" 53 "Reserved" 54 "Reserved" 55 "Reserved" 56 "Reserved" 57 "Reserved" 58 "Reserved" 59 "Reserved" 60 "Reserved" 61 "Reserved" 62 "Reserved" 63 "Reserved" ;
VAL_ 1331 ICC_AMPA2BChimeSoundReq 0 "Not Active" 1 "ON" 2 "OFF" 3 "Reserved" ;
VAL_ 1331 Set_AMPSoundFocus_2 0 "Not Active" 1 "Customized" 2 "All" 3 "Driver" 4 "Sleep" 5 "VIP" 6 "FrontRow" 7 "BackRow" ;
VAL_ 1331 ICC_AMPA2BKTVvoiceSoundReq 0 "Not Active" 1 "IESS OFF and KTV OFF（默认值)" 2 "IESS OFF and KTV ON" 3 "IESS ON and KTV OFF" 4 "IESS ON and KTV ON" ;
VAL_ 1331 ICC_MedStatusSet 0 "Not Active" 1 "ON" 2 "OFF" 3 "Not Used" ;
VAL_ 1331 ICC_MedAreaSet 0 "Not Active" 1 "Front Left" 2 "Front Right" 3 "Front Left and Right" 4 "2Row Left" 5 "2Row Right" 6 "2Row Left and 2Row Right" 7 "Front Left and 2Row Right" 8 "Front Right and 2Row Left" 9 "Front Left and 2Row Left" 10 "Front Right and 2Row Right" ;
VAL_ 1331 ICC_LeftElectricPedalsSet 0 "Not active" 1 "Open" 2 "Close" 3 "Reserved" ;
VAL_ 1331 ICC_RightElectricPedalsSet 0 "Not active" 1 "Open" 2 "Close" 3 "Reserved" ;
VAL_ 1331 ICC_NapAreaSet2 0 "Not Active" 1 "2Row Left" 2 "2Row Right" 3 "2Row Left and Right" 4 "Front Left and 2Row Right" 5 "Front Right and 2Row Left" 6 "Front Left and 2Row Left" 7 "Front Right and 2Row Right" ;
VAL_ 1331 ICC_DisplayAdjustrAngReq 0 "Not active" ;
VAL_ 1331 ICC_CMSMTouchSts 0 "Not active" 1 "Touch" 2 "No Touch" 3 "Reserved" ;
VAL_ 1333 ICC_SRFCmd 0 "Not Active" 1 "Open" 2 "Close" 3 "Tilt" ;
VAL_ 1333 ICC_SRFPercentCmd 0 "Not Active" 1 "0" 2 "10%" 3 "20%" 4 "30%" 5 "40%" 6 "50%" 7 "60%" 8 "70%" 9 "80%" 10 "90%" 11 "100%" ;
VAL_ 1333 ICC_CSunshadeReq 0 "Not Active" 1 "Open" 2 "Close" 3 "Half_Open" ;
VAL_ 1333 ICC_CSunshadePercentReq 0 "Not Active" 1 "0%" 2 "10%" 3 "20%" 4 "30%" 5 "40%" 6 "50%" 7 "60%" 8 "70%" 9 "80%" 10 "90%" 11 "100%" ;
VAL_ 1333 ICC_SunshadeCmd 0 "Not Active" 1 "Open" 2 "Close" 3 "Half_Open" ;
VAL_ 1333 ICC_SunshadePercentCmd 0 "Not Active" 1 "0%" 2 "10%" 3 "20%" 4 "30%" 5 "40%" 6 "50%" 7 "60%" 8 "70%" 9 "80%" 10 "90%" 11 "100%" ;
VAL_ 1335 ICC_SET_EPS_SteerReturnRmdSts 0 "Not Active" 1 "ON" 2 "OFF" 3 "reserved" ;
VAL_ 1335 ICC_SET_MFSShake 0 "Not Active" 1 "ON" 2 "OFF" 3 "reserved" ;
VAL_ 1335 ICC_DMS_1_DistractionLevel 0 "Not Active" 1 "DISTRACTION_LEVEL_LIGHT" 2 "DISTRACTION_LEVEL_MEDIUM" 3 "DISTRACTION_LEVEL_HEAVY" 4 "Reserved" 5 "Reserved" 6 "Reserved" 7 "Reserved" ;
VAL_ 1335 ICC_OverLoadWarnShieldSet 0 "Not Active" 1 "ON" 2 "OFF" 3 "reserved" ;
VAL_ 1335 ICC_BSWReq 0 "Not Active" 1 "ON" 2 "OFF" 3 "reserved" ;
VAL_ 1335 ICC_horizontalReq 0 "Not Active" 1 "ON" 2 "OFF" 3 "Not Used" ;
VAL_ 1337 ICC_SET_BT_ReduceWindSpeed 0 "Not_Active" 1 "ON" 2 "OFF" 3 "Reserved" ;
VAL_ 1337 ICC_SET_IPM_FirstBlowing 0 "Not Active" 1 "ON" 2 "OFF" 3 "Reserved" ;
VAL_ 1337 ICC_SET_IPM_BlowerDelay 0 "Not Active" 1 "ON" 2 "OFF" 3 "Reserved" ;
VAL_ 1337 ICC_SET_CirculationInTunnels 0 "Not Active" 1 "ON" 2 "OFF" 3 "Reserved" ;
VAL_ 1337 ICC_UVCLuminanceReq 0 "Not Active" 1 "high" 2 "lower" 3 "reserved" ;
VAL_ 1337 ICC_UVCControlReq 0 "Not Active" 1 "ON" 2 "OFF" 3 "AUTO" ;
VAL_ 1337 ICC_CrossCountryCoolingReq 0 "Not Active" 1 "ON" 2 "OFF" 3 "Reserved" ;
VAL_ 1337 ICC_KeepWarmReq 0 "Not Active" 1 "Open_AC" 2 "Open_NotAC" 3 "Closed" ;
VAL_ 1337 ICC_keepwarmSetTemperatureReq 0 "Not Active" 1 "Temperature 20°C" 2 "Temperature 25°C" 3 "Temperature 30°C" 4 "Temperature 35°C" 5 "Temperature 40°C" 6 "Temperature 45°C" 7 "Temperature 50°C" 8 "Temperature 55°C" 9 "Temperature 60°C" ;
VAL_ 1337 ICC_ParkingAirConditioning 0 "Not Active" 1 "Disable" 2 "AUTO" 3 "ventilate" ;
VAL_ 1337 ICC_CoolantFill_Req 0 "Not Active" 1 "ON" 2 "OFF" 3 "Reserved" ;
VAL_ 1337 ICC_FraganceLightoffReq 0 "No Active" 1 "FraganceLight_on" 2 "FraganceLight_off" 3 "Reserved" ;
VAL_ 1337 ICC_FraganceMemoffReq 0 "Not_Active" 1 "FraganceMem_on" 2 "FraganceMem_off" 3 "Reserved" ;
VAL_ 1337 ICC_AirPurgeReminderReq 0 "Not_Active" 1 "ON" 2 "OFF" 3 "Not_Used" ;
VAL_ 1337 ICC_BiochemicalFuncReq 0 "Not Active" 1 "ON" 2 "OFF" 3 "Reserved" ;
VAL_ 1337 ICC_TimedVentilationReq 0 "Not Active" 1 "ON" 2 "OFF" 3 "Reserved" ;
VAL_ 1337 ICC_PetmodeSetTemperature_L_C 31 "Not active" ;
VAL_ 1337 ICC_PetModeSetTemperature_R_C 31 "Not active" ;
VAL_ 1337 ICC_PetModeSetCLMOn 0 "Not Active" 1 "On" 2 "Off" 3 "Not Used" ;
VAL_ 1337 ICC_PetModeSetAutoKeySts 0 "Not Active" 1 "On" 2 "Off" 3 "Not Used" ;
VAL_ 1337 ICC_PetModeSetCirculationSts 0 "Not Active" 1 "Recirculation mode" 2 "Air circulation mode" 3 "Two-Layer Flow Mode" ;
VAL_ 1318 ICC_SET_TDL_Rhythm_Switch 0 "Not_Active" 1 "ON" 2 "OFF" 3 "reserved" ;
VAL_ 1318 ICC_SET_TDL_Switch 0 "Not_Active" 1 "ON" 2 "OFF" 3 "reserved" ;
VAL_ 1318 ICC_SET_TDL_ColourModeAdj 0 "Not_Active" 1 "Monochrome" 2 "panchromatic" 3 "OFF" 4 "Reserved" 5 "Reserved" 6 "Reserved" 7 "Reserved" ;
VAL_ 1318 ICC_VoiceWake 0 "Not_Active" 1 "ON" 2 "OFF" 3 "LHFawaken" 4 "LHRawaken" 5 "RHFawaken" 6 "RHRawaken" 7 "Reserved" ;
VAL_ 1318 ICC_TDL_RhythmReq 0 "Not_Active" 1 "Mode1" 2 "Mode2" 3 "Mode3" 4 "Mode4" 5 "Mode5" 6 "Mode6" 7 "Reserved" ;
VAL_ 1318 ICC_SET_ApiluminanceAdj 0 "Not_Active" 1 "Level1" 2 "Level2" 3 "Level3" 4 "Level4" 5 "Level5" 6 "Level6" 7 "Level7" 8 "Level8" 9 "Reserved" 10 "Reserved" 11 "Reserved" 12 "Reserved" 13 "Reserved" 14 "Reserved" 15 "Reserved" ;
VAL_ 1318 ICC_SET_MusicLoudness_120HZ 0 "Not_Active" 1 "Level_1" 2 "Level_2" 3 "Level_3" 4 "Level_4" 5 "Level_5" 6 "Level_6" 7 "Level_7" 8 "Level_8" 9 "Level_9" 10 "Level_10" 11 "Level_11" 12 "Level_12" 13 "Level_13" 14 "Level_14" 15 "Level_15" ;
VAL_ 1318 ICC_SET_MusicLoudness_250HZ 0 "Not_Active" 1 "Level_1" 2 "Level_2" 3 "Level_3" 4 "Level_4" 5 "Level_5" 6 "Level_6" 7 "Level_7" 8 "Level_8" 9 "Level_9" 10 "Level_10" 11 "Level_11" 12 "Level_12" 13 "Level_13" 14 "Level_14" 15 "Level_15" ;
VAL_ 1318 ICC_SET_MusicLoudness_500HZ 0 "Not_Active" 1 "Level_1" 2 "Level_2" 3 "Level_3" 4 "Level_4" 5 "Level_5" 6 "Level_6" 7 "Level_7" 8 "Level_8" 9 "Level_9" 10 "Level_10" 11 "Level_11" 12 "Level_12" 13 "Level_13" 14 "Level_14" 15 "Level_15" ;
VAL_ 1318 ICC_SET_MusicLoudness_1000HZ 0 "Not_Active" 1 "Level_1" 2 "Level_2" 3 "Level_3" 4 "Level_4" 5 "Level_5" 6 "Level_6" 7 "Level_7" 8 "Level_8" 9 "Level_9" 10 "Level_10" 11 "Level_11" 12 "Level_12" 13 "Level_13" 14 "Level_14" 15 "Level_15" ;
VAL_ 1318 ICC_SET_MusicLoudness_1500HZ 0 "Not_Active" 1 "Level_1" 2 "Level_2" 3 "Level_3" 4 "Level_4" 5 "Level_5" 6 "Level_6" 7 "Level_7" 8 "Level_8" 9 "Level_9" 10 "Level_10" 11 "Level_11" 12 "Level_12" 13 "Level_13" 14 "Level_14" 15 "Level_15" ;
VAL_ 1318 ICC_SET_MusicLoudness_2000HZ 0 "Not_Active" 1 "Level_1" 2 "Level_2" 3 "Level_3" 4 "Level_4" 5 "Level_5" 6 "Level_6" 7 "Level_7" 8 "Level_8" 9 "Level_9" 10 "Level_10" 11 "Level_11" 12 "Level_12" 13 "Level_13" 14 "Level_14" 15 "Level_15" ;
VAL_ 1318 ICC_SET_MusicLoudness_6000HZ 0 "Not_Active" 1 "Level_1" 2 "Level_2" 3 "Level_3" 4 "Level_4" 5 "Level_5" 6 "Level_6" 7 "Level_7" 8 "Level_8" 9 "Level_9" 10 "Level_10" 11 "Level_11" 12 "Level_12" 13 "Level_13" 14 "Level_14" 15 "Level_15" ;
VAL_ 1318 ICC_TDL_FlowLightSw 0 "Not_Active" 1 "ON" 2 "OFF" 3 "reserved" ;
VAL_ 1318 ICC_TDL_FlowLightModeAdj 0 "Not Active" 1 "mode1" 2 "mode2" 3 "mode3" 4 "mode4" 5 "mode5" 6 "mode6" 7 "Reserved" ;
VAL_ 1320 ICC_Chb_Req 0 "Not Active" 1 "Chb_ON" 2 "Chb_OFF" 3 "reserved" ;
VAL_ 1320 ICC_ChbMem_Req 0 "Not Active" 1 "ChbMem_ON" 2 "ChbMem_OFF" 3 "reserved" ;
VAL_ 1320 ICC_ChbDelay_Req 0 "Not Active" 1 "ChbDelay_ON" 2 "ChbDelay_OFF" 3 "reserved" ;
VAL_ 1320 ICC_ChbSterilization_Req 0 "Not Active" 1 "Chbsterilize_ON" 2 "Chbsterilize_OFF" 3 "reserved" ;
VAL_ 1320 ICC_ChbItemsLeft_Req 0 "Not Active" 1 "Chbhanddown_ON" 2 "Chbhanddown_OFF" 3 "reserved" ;
VAL_ 1320 ICC_ParkingRadarSwSet 0 "Not active" 1 "ON" 2 "OFF" 3 "Reserved" ;
VAL_ 1320 ICC_ChbCoolset_Req 0 "Not_Active" 1 "ChbCoolset_-6" 2 "ChbCoolset_-5" 3 "ChbCoolset_-4" 4 "ChbCoolset_-3" 5 "ChbCoolset_-2" 6 "ChbCoolset_-1" 7 "ChbCoolset_0" 8 "ChbCoolset_1" 9 "ChbCoolset_2" 10 "ChbCoolset_3" 11 "ChbCoolset_4" 12 "ChbCoolset_5" 13 "ChbCoolset_6" 14 "ChbCoolset_-18" 15 "ChbCoolset_-17" 16 "ChbCoolset_-16" 17 "ChbCoolset_-15" 18 "ChbCoolset_-14" 19 "ChbCoolset_-13" 20 "ChbCoolset_-12" 21 "ChbCoolset_-11" 22 "ChbCoolset_-10" 23 "ChbCoolset_-9" 24 "ChbCoolset_-8" 25 "ChbCoolset_-7" 26 "Reserved" 27 "Reserved" 28 "Reserved" 29 "Reserved" 30 "Reserved" 31 "Reserved" ;
VAL_ 1320 ICC_ChbCoolorheat_Req 0 "NotActive" 1 "ChbCool_on" 2 "ChbHeat_on" 3 "Close" 4 "ColdDrinkMode" 5 "IceCreamMode" 6 "WarmMilkMode" 7 "WarmDrinkMode" ;
VAL_ 1320 ICC_ChbHeatset_Req 0 "Not Active" 1 "ChbHeatset_35" 2 "ChbHeatset_36" 3 "ChbHeatset_37" 4 "ChbHeatset_38" 5 "ChbHeatset_39" 6 "ChbHeatset_40" 7 "ChbHeatset_41" 8 "ChbHeatset_42" 9 "ChbHeatset_43" 10 "ChbHeatset_44" 11 "ChbHeatset_45" 12 "ChbHeatset_46" 13 "ChbHeatset_47" 14 "ChbHeatset_48" 15 "ChbHeatset_49" 16 "ChbHeatset_50" ;
VAL_ 1360 ICC_LISD_DisplaySwitch 0 "Default value" 1 "Display ON" 2 "Display OFF" 3 "Reserved" ;
VAL_ 1360 ICC_LISD_ParkingShowCMD 0 "Default value" 1 "ON" 2 "OFF" 3 "Reserved" ;
VAL_ 1360 ICC_RoofCampLampSetL 0 "Not_Active" 1 "ON" 2 "OFF" 3 "reserved" ;
VAL_ 1360 ICC_RISD_DisplaySwitch 0 "Default value" 1 "Display ON" 2 "Display OFF" 3 "Reserved" ;
VAL_ 1360 ICC_RISD_ParkingShowCMD 0 "Default value" 1 "ON" 2 "OFF" 3 "Reserved" ;
VAL_ 1360 ICC_RoofCampLampSetR 0 "Not_Active" 1 "ON" 2 "OFF" 3 "reserved" ;
VAL_ 1360 ICC_LogoParkingReq 0 "Not Active" 1 "ON" 2 "OFF" 3 "Reserved" ;
VAL_ 1360 ICC_LogoChargingReq 0 "Not Active" 1 "ON" 2 "OFF" 3 "Reserved" ;
VAL_ 1360 ICC_DRLSw 0 "Not active" 1 "ON" 2 "OFF" 3 "Reserved" ;
VAL_ 1360 ICC_TopLightSet 0 "Not_Active" 1 "ON" 2 "OFF" 3 "reserved" ;
VAL_ 1360 ICC_APillarYellowAmbientSet 0 "Not_Active" 1 "ON" 2 "OFF" 3 "reserved" ;
VAL_ 1360 ICC_APillarWhiteAmbientSet 0 "Not_Active" 1 "ON" 2 "OFF" 3 "reserved" ;
VAL_ 1360 ICC_LISD_ParkingShowMod 0 "Default value" 1 "Mode1" 2 "Mode2" 3 "Mode3" 4 "Mode4" 5 "Reserved" 6 "Reserved" 7 "Reserved" 8 "Reserved" 9 "Reserved" 10 "Reserved" 11 "Reserved" 12 "Reserved" 13 "Reserved" 14 "Reserved" 15 "Reserved" ;
VAL_ 1360 ICC_RISD_ParkingShowMod 0 "Default value" 1 "Mode1" 2 "Mode2" 3 "Mode3" 4 "Mode4" 5 "Reserved" 6 "Reserved" 7 "Reserved" 8 "Reserved" 9 "Reserved" 10 "Reserved" 11 "Reserved" 12 "Reserved" 13 "Reserved" 14 "Reserved" 15 "Reserved" ;
VAL_ 1360 ICC_APillarSpotLampSet 0 "Not_Active" 1 "ON" 2 "OFF" 3 "reserved" ;
VAL_ 1360 ICC_PenetrationLampSetF 0 "Not_Active" 1 "ON" 2 "OFF" 3 "reserved" ;
VAL_ 1360 ICC_MusicLampShowSW 0 "Not active" 1 "OFF" 2 "ON" 3 "Reserved" ;
VAL_ 1360 ICC_LogoColorReq 0 "Not_Active" ;
VAL_ 1360 ICC_XDriveMode 0 "Not Active" 1 "unidentifiable" 2 "Normal" 3 "SNOW" 4 "MUD" 5 "ROCK" 6 "SAND" 7 "WATERSURFACE" 8 "Normal" 9 "SNOW" 10 "MUD" 11 "ROCK" 12 "SAND" 13 "WATERSURFACE" 14 "Normal" 15 "SNOW" 16 "MUD" 17 "ROCK" 18 "SAND" 19 "Reserved" 20 "Reserved" 21 "Reserved" 22 "Reserved" 23 "Reserved" 24 "Reserved" 25 "Reserved" 26 "Reserved" 27 "Reserved" 28 "Reserved" 29 "Reserved" 30 "Reserved" 31 "Reserved" ;
SIG_GROUP_ 1335 New_Signal_Group_537 1 : ICC_SandABSSw_537h ICC_SandABSCmd_537h ICC_TrekThroughReq_537h ICC_InflateReq_537h ICC_UndergroundModeReq_537h ICC_horizontalReq ICC_BSWReq ICC_OverLoadWarnShieldSet ICC_DMS_1_DistractionLevel ICC_SET_MFSShake ICC_SET_EPS_SteerReturnRmdSts ICC_RolloverSetCmd New_Signal_537_1 New_Signal_537_3;
